AUTOSAR XML (schema 4-2-1)
package /VehicleProject
  system System
package /TP
  can tp config FD1_CAN: communication-cluster=FD1_CAN, can-tp-ecu{cycle-time-main-function=0.005, ecu-instance=PSCM_FD}
    can tp channel TPCH: channel-id=0, channel-mode=FULL-DUPLEX-MODE
    can-tp-connection addressing-format=STANDARD, can-tp-channel=TPCH, data-pdu=TesterFunctionalReq_FD1_Tp_oFD1_CAN, receiver=TN_PSCM_FD_FD, ta-type=FUNCTIONAL-CAN-FD, tp-sdu=TesterFunctionalReq_FD1_oFD1_CAN, transmitter=TN_TSTR_FD:
      ident TesterFunctionalReq_FD1_FD_oTN_TSTR_FD
    can-tp-connection addressing-format=STANDARD, can-tp-channel=TPCH, data-pdu=TesterFunctionalReq_FD1_Tp_oFD1_CAN_20, receiver=TN_PSCM_FD, ta-type=FUNCTIONAL, tp-sdu=TesterFunctionalReq_FD1_oFD1_CAN_20, transmitter=TN_TSTR:
      ident TesterFunctionalReq_FD1_oTN_TSTR
    can-tp-connection addressing-format=STANDARD, can-tp-channel=TPCH, data-pdu=TesterPhysicalReqPSCM_FD1_Tp_oFD1_CAN_20, flow-control-pdu=TesterPhysicalResPSCM_FD1_Tp_oFD1_CAN_20, receiver=TN_PSCM_FD, ta-type=PHYSICAL, tp-sdu=TesterPhysicalReqPSCM_FD1_oFD1_CAN_20, transmitter=TN_TSTR:
      ident TesterPhysicalReqPSCM_FD1_oTN_PSCM_FD
    can-tp-connection addressing-format=STANDARD, can-tp-channel=TPCH, data-pdu=TesterPhysicalReqPSCM_FD1_Tp_oFD1_CAN, flow-control-pdu=TesterPhysicalResPSCM_FD1_Tp_oFD1_CAN, receiver=TN_PSCM_FD_FD, ta-type=PHYSICAL-CAN-FD, tp-sdu=TesterPhysicalReqPSCM_FD1_oFD1_CAN, transmitter=TN_TSTR_FD:
      ident TesterPhysicalReqPSCM_FD1_oTN_PSCM_FD_FD
    can-tp-connection addressing-format=STANDARD, can-tp-channel=TPCH, data-pdu=TesterPhysicalResPSCM_FD1_Tp_oFD1_CAN_20, flow-control-pdu=TesterPhysicalReqPSCM_FD1_Tp_oFD1_CAN_20, receiver=TN_TSTR, ta-type=PHYSICAL, tp-sdu=TesterPhysicalResPSCM_FD1_oFD1_CAN_20, transmitter=TN_PSCM_FD:
      ident TesterPhysicalResPSCM_FD1_oTN_PSCM_FD
    can-tp-connection addressing-format=STANDARD, can-tp-channel=TPCH, data-pdu=TesterPhysicalResPSCM_FD1_Tp_oFD1_CAN, flow-control-pdu=TesterPhysicalReqPSCM_FD1_Tp_oFD1_CAN, receiver=TN_TSTR_FD, ta-type=PHYSICAL-CAN-FD, tp-sdu=TesterPhysicalResPSCM_FD1_oFD1_CAN, transmitter=TN_PSCM_FD_FD:
      ident TesterPhysicalResPSCM_FD1_oTN_PSCM_FD_FD
    4 x can tp node:
      TN_PSCM_FD: connector=CN_FD1_CAN
      TN_PSCM_FD_FD: connector=CN_FD1_CAN
      TN_TSTR
      TN_TSTR_FD
package /Cluster
  can cluster FD1_CAN: baudrate=500000, protocol-name=CAN, can-fd-baudrate=500000  # FD1_CAN_P702_GASD_MY21_V05 | New CAN FD network
    can physical channel CHNL: comm-connectors=CN_FD1_CAN
      frame ABS_BrkBst_Data_FD1_oFD1_CAN: id 0x4B0, to PSCM_FD, frame-length=8, can-addressing-mode=STANDARD, can-frame-rx-behavior=ANY, can-frame-tx-behavior=CAN-FD
        pdu ABS_BrkBst_Data_FD1_oFD1_CAN: length=8, minimum-delay=0.01, transmission-mode-false-timing=cyclic-timing={time-offset=0, time-period=0.02}, transmission-mode-true-timing=cyclic-timing={time-offset=0, time-period=0.02}, unused-bit-pattern=0
          signal YawStabilityIndex_oABS_BrkBst_Data_FD1_oFD1_CAN: start 0, 9 bit, big-endian, init-value=256, base-type=uint16, compu-method=CM_YawStabilityIndex, unit=U_p, transfer-property=PENDING, to PSCM_FD
      frame ActiveFrontStrg_Stat2_FD1_oFD1_CAN: id 0x8A, to PSCM_FD, frame-length=8, can-addressing-mode=STANDARD, can-frame-rx-behavior=ANY, can-frame-tx-behavior=CAN-FD
        pdu ActiveFrontStrg_Stat2_FD1_oFD1_CAN: length=8, minimum-delay=0.02, unused-bit-pattern=0
          signal SteWhlRelCalib_An_Sns_oActiveFrontStrg_Stat2_FD1_oFD1_CAN: start 15, 15 bit, big-endian, init-value=0, base-type=uint16, compu-method=CM_SteWhlRelCalib_An_Sns, unit=U_deg, transfer-property=PENDING, to PSCM_FD  # Signal is not transmitted on vehicles where PSCM is transmitting the message that contains this signal. Signal data set to 0x0 for ABS only vehicle option content
      frame APIM_Send_Signals_2_FD1_oFD1_CAN: id 0x215, to PSCM_FD, frame-length=8, can-addressing-mode=STANDARD, can-frame-rx-behavior=ANY, can-frame-tx-behavior=CAN-FD
        pdu APIM_Send_Signals_2_FD1_oFD1_CAN: length=8, minimum-delay=0.02, unused-bit-pattern=0
          signal TrlrAidMde_D_Rq_oAPIM_Send_Signals_2_FD1_oFD1_CAN: start 5, 2 bit, big-endian, init-value=0, base-type=uint8, compu-method=CM_TrlrAidMde_D_Rq, unit=U_SED, transfer-property=PENDING, to PSCM_FD
      frame APIM_Send_Signals1_FD1_oFD1_CAN: id 0x3F1, to PSCM_FD, frame-length=8, can-addressing-mode=STANDARD, can-frame-rx-behavior=ANY, can-frame-tx-behavior=CAN-FD  # APIM Tx
        pdu APIM_Send_Signals1_FD1_oFD1_CAN: length=8, minimum-delay=0.02, unused-bit-pattern=0
          signal TrlrAidCancl_B_Rq_oAPIM_Send_Signals1_FD1_oFD1_CAN: start 48, 1 bit, big-endian, init-value=0, base-type=boolean, compu-method=CM_TrlrAidCancl_B_Rq, unit=U_SED, transfer-property=PENDING, to PSCM_FD
      frame Body_Info_4_FD1_oFD1_CAN: id 0x242, to PSCM_FD, frame-length=8, can-addressing-mode=STANDARD, can-frame-rx-behavior=ANY, can-frame-tx-behavior=CAN-FD
        pdu Body_Info_4_FD1_oFD1_CAN: length=8, minimum-delay=0.02, unused-bit-pattern=0
          signal BattULo_U_Actl_oBody_Info_4_FD1_oFD1_CAN: start 39, 8 bit, big-endian, init-value=255, base-type=uint8, compu-method=CM_BattULo_U_Actl, unit=U_volt, transfer-property=PENDING, to PSCM_FD
      frame BodyInfo_3_FD1_oFD1_CAN: id 0x3B3, to PSCM_FD, frame-length=8, can-addressing-mode=STANDARD, can-frame-rx-behavior=ANY, can-frame-tx-behavior=CAN-FD
        pdu BodyInfo_3_FD1_oFD1_CAN: length=8, minimum-delay=0.02, unused-bit-pattern=0
          signal Ignition_Status_oBodyInfo_3_FD1_oFD1_CAN: start 7, 4 bit, big-endian, init-value=0, base-type=uint8, compu-method=CM_Ignition_Status, unit=U_SED, transfer-property=PENDING, to PSCM_FD
          signal LifeCycMde_D_Actl_oBodyInfo_3_FD1_oFD1_CAN: start 53, 4 bit, big-endian, init-value=0, base-type=uint8, compu-method=CM_LifeCycMde_D_Actl, unit=U_SED, transfer-property=PENDING, to PSCM_FD
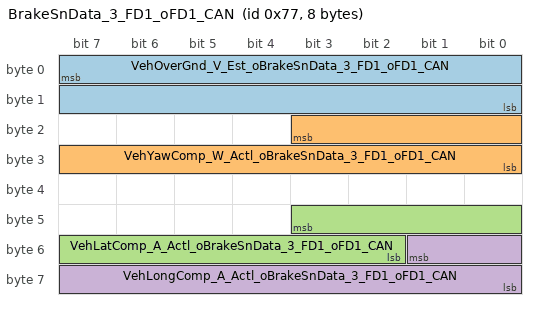
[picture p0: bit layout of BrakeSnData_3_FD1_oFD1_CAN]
      frame BrakeSnData_3_FD1_oFD1_CAN: id 0x77, to PSCM_FD, frame-length=8, can-addressing-mode=STANDARD, can-frame-rx-behavior=ANY, can-frame-tx-behavior=CAN-FD
        pdu BrakeSnData_3_FD1_oFD1_CAN: length=8, minimum-delay=0.01, transmission-mode-false-timing=cyclic-timing={time-offset=0, time-period=0.02}, transmission-mode-true-timing=cyclic-timing={time-offset=0, time-period=0.02}, unused-bit-pattern=0
          signal VehOverGnd_V_Est_oBrakeSnData_3_FD1_oFD1_CAN: start 7, 16 bit, big-endian, init-value=0, base-type=uint16, compu-method=CM_VehOverGnd_V_Est, unit=U_kph, transfer-property=PENDING, to PSCM_FD
          signal VehYawComp_W_Actl_oBrakeSnData_3_FD1_oFD1_CAN: start 19, 12 bit, big-endian, init-value=4094, base-type=uint16, compu-method=CM_VehYawComp_W_Actl, unit=U_degYs, transfer-property=PENDING, to PSCM_FD
          signal VehLatComp_A_Actl_oBrakeSnData_3_FD1_oFD1_CAN: start 43, 10 bit, big-endian, init-value=1022, base-type=uint16, compu-method=CM_VehLatComp_A_Actl, unit=U_mYsX2, transfer-property=PENDING, to PSCM_FD
          signal VehLongComp_A_Actl_oBrakeSnData_3_FD1_oFD1_CAN: start 49, 10 bit, big-endian, init-value=1022, base-type=uint16, compu-method=CM_VehLongComp_A_Actl, unit=U_mYsX2, transfer-property=PENDING, to PSCM_FD
      frame BrakeSnData_4_FD1_oFD1_CAN: id 0x7D, to PSCM_FD, frame-length=8, can-addressing-mode=STANDARD, can-frame-rx-behavior=ANY, can-frame-tx-behavior=CAN-FD
        pdu BrakeSnData_4_FD1_oFD1_CAN: length=8, minimum-delay=0.01, transmission-mode-false-timing=cyclic-timing={time-offset=0, time-period=0.02}, transmission-mode-true-timing=cyclic-timing={time-offset=0, time-period=0.02}, unused-bit-pattern=0
          signal BrkTot_Tq_Actl_oBrakeSnData_4_FD1_oFD1_CAN: start 27, 13 bit, big-endian, init-value=0, base-type=uint16, compu-method=CM_BrkTot_Tq_Actl, unit=U_Nm, transfer-property=PENDING, to PSCM_FD
          signal VehVertComp_A_Actl_oBrakeSnData_4_FD1_oFD1_CAN: start 45, 10 bit, big-endian, init-value=1022, base-type=uint16, compu-method=CM_VehVertComp_A_Actl, unit=U_mYsX2, transfer-property=PENDING, to PSCM_FD
      frame BrakeSnData_5_FD1_oFD1_CAN: id 0x76, to PSCM_FD, frame-length=8, can-addressing-mode=STANDARD, can-frame-rx-behavior=ANY, can-frame-tx-behavior=CAN-FD
        pdu BrakeSnData_5_FD1_oFD1_CAN: length=8, minimum-delay=0.02, transmission-mode-false-timing={cyclic-timing={time-offset=0, time-period=0.5}, event-controlled-timing={number-of-repetitions=0, repetition-period=0}}, transmission-mode-true-timing={cyclic-timing={time-offset=0, time-period=0.5}, event-controlled-timing={number-of-repetitions=0, repetition-period=0}}, unused-bit-pattern=0
          signal DrvSte_D_Stat_oBrakeSnData_5_FD1_oFD1_CAN: start 19, 4 bit, big-endian, init-value=0, base-type=uint8, compu-method=CM_DrvSte_D_Stat, unit=U_SED, transfer-property=TRIGGERED-ON-CHANGE-WITHOUT-REPETITION, to PSCM_FD
          signal DrvSte_Tq_Rq_oBrakeSnData_5_FD1_oFD1_CAN: start 31, 8 bit, big-endian, init-value=128, base-type=uint8, compu-method=CM_DrvSte_Tq_Rq, unit=U_Nm, transfer-property=PENDING, to PSCM_FD
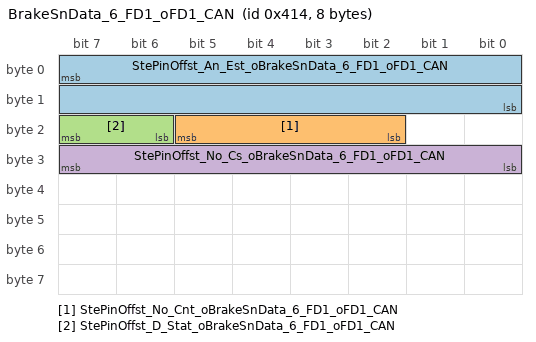
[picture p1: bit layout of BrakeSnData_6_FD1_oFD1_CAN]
      frame BrakeSnData_6_FD1_oFD1_CAN: id 0x414, to PSCM_FD, frame-length=8, can-addressing-mode=STANDARD, can-frame-rx-behavior=ANY, can-frame-tx-behavior=CAN-FD
        pdu BrakeSnData_6_FD1_oFD1_CAN: length=8, minimum-delay=0.02, transmission-mode-false-timing=cyclic-timing={time-offset=0, time-period=0.1}, transmission-mode-true-timing=cyclic-timing={time-offset=0, time-period=0.1}, unused-bit-pattern=0
          signal StePinOffst_An_Est_oBrakeSnData_6_FD1_oFD1_CAN: start 7, 16 bit, big-endian, init-value=65534, base-type=uint16, compu-method=CM_StePinOffst_An_Est, unit=U_degrees, transfer-property=PENDING, to PSCM_FD  # SASM will transmit these signals on vehicles with SASM and without PSCM. SCCM will not Tx this signal when SASM is present.
          signal StePinOffst_No_Cnt_oBrakeSnData_6_FD1_oFD1_CAN: start 21, 4 bit, big-endian, init-value=0, base-type=uint8, compu-method=CM_StePinOffst_No_Cnt, unit=unitless, transfer-property=PENDING, to PSCM_FD
          signal StePinOffst_D_Stat_oBrakeSnData_6_FD1_oFD1_CAN: start 23, 2 bit, big-endian, init-value=0, base-type=uint8, compu-method=CM_StePinOffst_D_Stat, unit=U_SED, transfer-property=PENDING, to PSCM_FD
          signal StePinOffst_No_Cs_oBrakeSnData_6_FD1_oFD1_CAN: start 31, 8 bit, big-endian, init-value=0, base-type=uint8, compu-method=CM_StePinOffst_No_Cs, unit=Unitless, transfer-property=PENDING, to PSCM_FD  # Signal not transmitted on gas variants.
      frame BrakeSysFeatures_3_oFD1_CAN: id 0x41E, to PSCM_FD, frame-length=8, can-addressing-mode=STANDARD, can-frame-rx-behavior=ANY, can-frame-tx-behavior=CAN-FD
        pdu BrakeSysFeatures_3_oFD1_CAN: length=8, minimum-delay=0.02, transmission-mode-false-timing={cyclic-timing={time-offset=0, time-period=1}, event-controlled-timing={number-of-repetitions=0, repetition-period=0}}, transmission-mode-true-timing={cyclic-timing={time-offset=0, time-period=1}, event-controlled-timing={number-of-repetitions=0, repetition-period=0}}, unused-bit-pattern=0
          signal SelDrvMdeChassis2_D_Rq_oBrakeSysFeatures_3_oFD1_CAN: start 45, 5 bit, big-endian, init-value=0, base-type=uint8, compu-method=CM_SelDrvMdeChassis2_D_Rq, unit=U_SED, transfer-property=TRIGGERED-ON-CHANGE-WITHOUT-REPETITION, to PSCM_FD
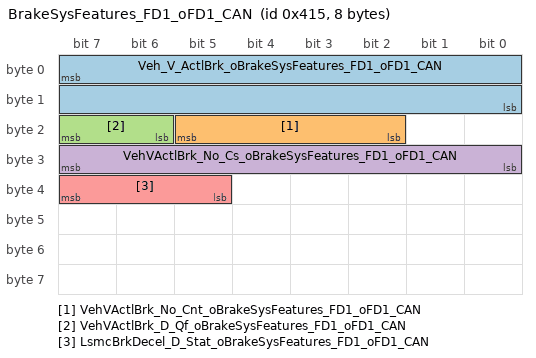
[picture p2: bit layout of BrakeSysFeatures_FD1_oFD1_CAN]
      frame BrakeSysFeatures_FD1_oFD1_CAN: id 0x415, to PSCM_FD, frame-length=8, can-addressing-mode=STANDARD, can-frame-rx-behavior=ANY, can-frame-tx-behavior=CAN-FD
        pdu BrakeSysFeatures_FD1_oFD1_CAN: length=8, minimum-delay=0.01, transmission-mode-false-timing=cyclic-timing={time-offset=0, time-period=0.02}, transmission-mode-true-timing=cyclic-timing={time-offset=0, time-period=0.02}, unused-bit-pattern=0
          signal Veh_V_ActlBrk_oBrakeSysFeatures_FD1_oFD1_CAN: start 7, 16 bit, big-endian, init-value=0, base-type=uint16, compu-method=CM_Veh_V_ActlBrk, unit=U_kph, transfer-property=PENDING, to PSCM_FD
          signal VehVActlBrk_No_Cnt_oBrakeSysFeatures_FD1_oFD1_CAN: start 21, 4 bit, big-endian, init-value=0, base-type=uint8, compu-method=CM_VehVActlBrk_No_Cnt, unit=Unitless, transfer-property=PENDING, to PSCM_FD
          signal VehVActlBrk_D_Qf_oBrakeSysFeatures_FD1_oFD1_CAN: start 23, 2 bit, big-endian, init-value=0, base-type=uint8, compu-method=CM_VehVActlBrk_D_Qf, unit=U_SED, transfer-property=PENDING, to PSCM_FD
          signal VehVActlBrk_No_Cs_oBrakeSysFeatures_FD1_oFD1_CAN: start 31, 8 bit, big-endian, init-value=0, base-type=uint8, compu-method=CM_VehVActlBrk_No_Cs, unit=Unitless, transfer-property=PENDING, to PSCM_FD
          signal LsmcBrkDecel_D_Stat_oBrakeSysFeatures_FD1_oFD1_CAN: start 39, 3 bit, big-endian, init-value=0, base-type=uint8, compu-method=CM_LsmcBrkDecel_D_Stat, unit=U_SED, transfer-property=PENDING, to PSCM_FD
      frame Climate_Control_Data_FD1_oFD1_CAN: id 0x41A, to PSCM_FD, frame-length=8, can-addressing-mode=STANDARD, can-frame-rx-behavior=ANY, can-frame-tx-behavior=CAN-FD
        pdu Climate_Control_Data_FD1_oFD1_CAN: length=8, minimum-delay=0.02, unused-bit-pattern=0
          signal Outside_Air_Temp_Stat_oClimate_Control_Data_FD1_oFD1_CAN: start 7, 8 bit, big-endian, init-value=254, base-type=uint8, compu-method=CM_Outside_Air_Temp_Stat, unit=U_Degrees_C, transfer-property=PENDING, to PSCM_FD  # Filtered value, i.e. same as disply for customer
      frame Cluster_Info1_FD1_oFD1_CAN: id 0x430, to PSCM_FD, frame-length=8, can-addressing-mode=STANDARD, can-frame-rx-behavior=ANY, can-frame-tx-behavior=CAN-FD
        pdu Cluster_Info1_FD1_oFD1_CAN: length=8, minimum-delay=0.02, unused-bit-pattern=0
          signal OdometerMasterValue_oCluster_Info1_FD1_oFD1_CAN: start 15, 24 bit, big-endian, init-value=0, base-type=uint32, compu-method=CM_OdometerMasterValue, unit=U_km, transfer-property=PENDING, to PSCM_FD
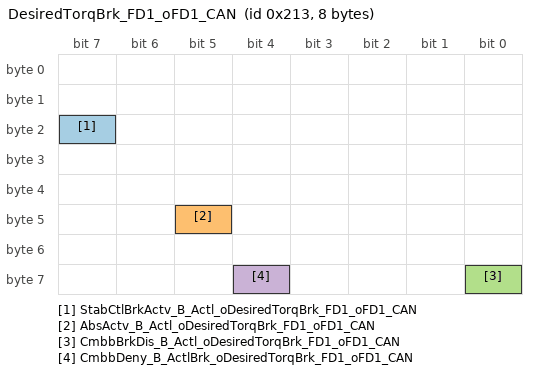
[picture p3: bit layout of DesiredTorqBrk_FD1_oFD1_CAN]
      frame DesiredTorqBrk_FD1_oFD1_CAN: id 0x213, to PSCM_FD, frame-length=8, can-addressing-mode=STANDARD, can-frame-rx-behavior=ANY, can-frame-tx-behavior=CAN-FD  # When PBM is present use 0x41B for PrkMsgTxt_D_Rq, PrkBrkRedLamp_D_Rq, PrkBrkYwLamp_D_Rq source signals otherwise ABS will source from 0x213.
        pdu DesiredTorqBrk_FD1_oFD1_CAN: length=8, minimum-delay=0.01, transmission-mode-false-timing=cyclic-timing={time-offset=0, time-period=0.02}, transmission-mode-true-timing=cyclic-timing={time-offset=0, time-period=0.02}, unused-bit-pattern=0
          signal StabCtlBrkActv_B_Actl_oDesiredTorqBrk_FD1_oFD1_CAN: start 23, 1 bit, big-endian, init-value=0, base-type=boolean, compu-method=CM_StabCtlBrkActv_B_Actl, unit=U_SED, transfer-property=PENDING, to PSCM_FD
          signal AbsActv_B_Actl_oDesiredTorqBrk_FD1_oFD1_CAN: start 45, 1 bit, big-endian, init-value=0, base-type=boolean, compu-method=CM_AbsActv_B_Actl, unit=U_SED, transfer-property=PENDING, to PSCM_FD
          signal CmbbBrkDis_B_Actl_oDesiredTorqBrk_FD1_oFD1_CAN: start 56, 1 bit, big-endian, init-value=0, base-type=boolean, compu-method=CM_CmbbBrkDis_B_Actl, unit=U_SED, transfer-property=PENDING, to PSCM_FD
          signal CmbbDeny_B_ActlBrk_oDesiredTorqBrk_FD1_oFD1_CAN: start 60, 1 bit, big-endian, init-value=0, base-type=boolean, compu-method=CM_CmbbDeny_B_ActlBrk, unit=U_SED, transfer-property=PENDING, to PSCM_FD
      frame EngBrakeData_FD1_oFD1_CAN: id 0x165, to PSCM_FD, frame-length=8, can-addressing-mode=STANDARD, can-frame-rx-behavior=ANY, can-frame-tx-behavior=CAN-FD
        pdu EngBrakeData_FD1_oFD1_CAN: length=8, minimum-delay=0.01, transmission-mode-false-timing=cyclic-timing={time-offset=0, time-period=0.02}, transmission-mode-true-timing=cyclic-timing={time-offset=0, time-period=0.02}, unused-bit-pattern=0
          signal BpedDrvAppl_D_Actl_oEngBrakeData_FD1_oFD1_CAN: start 5, 2 bit, big-endian, init-value=1, base-type=uint8, compu-method=CM_BpedDrvAppl_D_Actl, unit=U_SED, transfer-property=PENDING, to PSCM_FD  # CCMGenSigTimeoutTime=1000
          signal BPedDrvAppl_D_QF_oEngBrakeData_FD1_oFD1_CAN: start 15, 2 bit, big-endian, init-value=1, base-type=uint8, compu-method=CM_BPedDrvAppl_D_QF, unit=U_SED, transfer-property=PENDING, to PSCM_FD
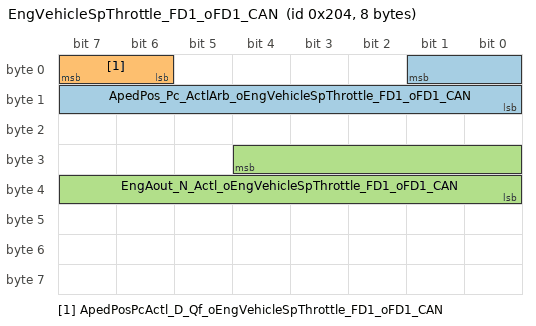
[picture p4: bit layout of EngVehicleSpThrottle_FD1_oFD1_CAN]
      frame EngVehicleSpThrottle_FD1_oFD1_CAN: id 0x204, to PSCM_FD, frame-length=8, can-addressing-mode=STANDARD, can-frame-rx-behavior=ANY, can-frame-tx-behavior=CAN-FD
        pdu EngVehicleSpThrottle_FD1_oFD1_CAN: length=8, minimum-delay=0, transmission-mode-false-timing=cyclic-timing={time-offset=0, time-period=0.01}, transmission-mode-true-timing=cyclic-timing={time-offset=0, time-period=0.01}, unused-bit-pattern=0
          signal ApedPos_Pc_ActlArb_oEngVehicleSpThrottle_FD1_oFD1_CAN: start 1, 10 bit, big-endian, init-value=0, base-type=uint16, compu-method=CM_ApedPos_Pc_ActlArb, unit=U_p, transfer-property=PENDING, to PSCM_FD  # ABSGenSigTimeoutTime=1000
          signal ApedPosPcActl_D_Qf_oEngVehicleSpThrottle_FD1_oFD1_CAN: start 7, 2 bit, big-endian, init-value=1, base-type=uint8, compu-method=CM_ApedPosPcActl_D_Qf, unit=U_SED, transfer-property=PENDING, to PSCM_FD
          signal EngAout_N_Actl_oEngVehicleSpThrottle_FD1_oFD1_CAN: start 28, 13 bit, big-endian, init-value=0, base-type=uint16, compu-method=CM_EngAout_N_Actl, unit=U_rpm, transfer-property=PENDING, to PSCM_FD
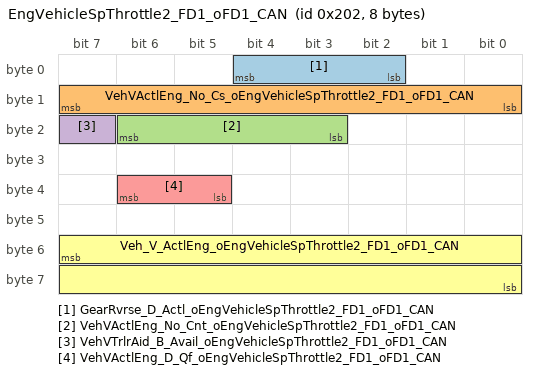
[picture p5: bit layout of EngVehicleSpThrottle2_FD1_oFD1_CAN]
      frame EngVehicleSpThrottle2_FD1_oFD1_CAN: id 0x202, to PSCM_FD, frame-length=8, can-addressing-mode=STANDARD, can-frame-rx-behavior=ANY, can-frame-tx-behavior=CAN-FD
        pdu EngVehicleSpThrottle2_FD1_oFD1_CAN: length=8, minimum-delay=0.01, transmission-mode-false-timing=cyclic-timing={time-offset=0, time-period=0.02}, transmission-mode-true-timing=cyclic-timing={time-offset=0, time-period=0.02}, unused-bit-pattern=0
          signal GearRvrse_D_Actl_oEngVehicleSpThrottle2_FD1_oFD1_CAN: start 4, 3 bit, big-endian, init-value=7, base-type=uint8, compu-method=CM_GearRvrse_D_Actl, unit=U_SED, transfer-property=PENDING, to PSCM_FD  # Do not implement GearRvrse_D_Actl until eTracker 8804151 is approved, 11/24/09
          signal VehVActlEng_No_Cs_oEngVehicleSpThrottle2_FD1_oFD1_CAN: start 15, 8 bit, big-endian, init-value=0, base-type=uint8, compu-method=CM_VehVActlEng_No_Cs, unit=Unitless, transfer-property=PENDING, to PSCM_FD
          signal VehVActlEng_No_Cnt_oEngVehicleSpThrottle2_FD1_oFD1_CAN: start 22, 4 bit, big-endian, init-value=0, base-type=uint8, compu-method=CM_VehVActlEng_No_Cnt, unit=Unitless, transfer-property=PENDING, to PSCM_FD
          signal VehVTrlrAid_B_Avail_oEngVehicleSpThrottle2_FD1_oFD1_CAN: start 23, 1 bit, big-endian, init-value=0, base-type=boolean, compu-method=CM_VehVTrlrAid_B_Avail, unit=U_SED, transfer-property=PENDING, to PSCM_FD
          signal VehVActlEng_D_Qf_oEngVehicleSpThrottle2_FD1_oFD1_CAN: start 38, 2 bit, big-endian, init-value=0, base-type=uint8, compu-method=CM_VehVActlEng_D_Qf, unit=U_SED, transfer-property=PENDING, to PSCM_FD
          signal Veh_V_ActlEng_oEngVehicleSpThrottle2_FD1_oFD1_CAN: start 55, 16 bit, big-endian, init-value=0, base-type=uint16, compu-method=CM_Veh_V_ActlEng, unit=U_kph, transfer-property=PENDING, to PSCM_FD
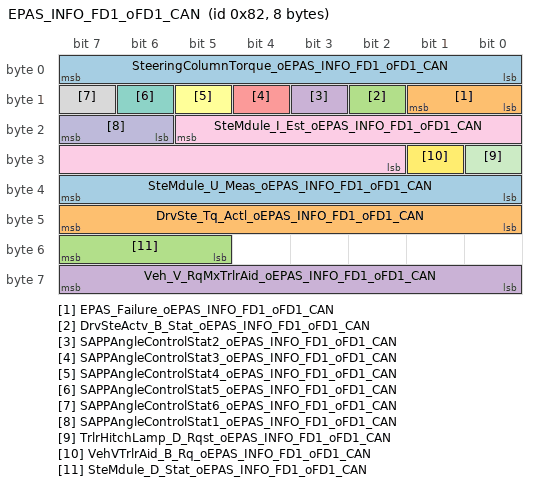
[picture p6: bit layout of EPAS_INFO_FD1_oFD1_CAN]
      frame EPAS_INFO_FD1_oFD1_CAN: id 0x82, from PSCM_FD, frame-length=8, variation-point=post-build-variant-condition{matching-criterion=Communication, value=0}, can-addressing-mode=STANDARD, can-frame-rx-behavior=ANY, can-frame-tx-behavior=CAN-FD  # drecker 10/23/09 Need SAPP in sync w/Strg Torque for proper PAM interpretation, else fault msg's displayed FP@20ms IPC needs EPAS_Failure for msg to driver. Not map w/Lane Assist FP@30s FP), save bandwidth if feature not on vehicle
        pdu EPAS_INFO_FD1_oFD1_CAN: length=8, minimum-delay=0.01, transmission-mode-false-timing=cyclic-timing={time-offset=0, time-period=0.02}, transmission-mode-true-timing=cyclic-timing={time-offset=0, time-period=0.02}, unused-bit-pattern=0
          signal SteeringColumnTorque_oEPAS_INFO_FD1_oFD1_CAN: start 7, 8 bit, big-endian, init-value=254, base-type=uint8, compu-method=CM_SteeringColumnTorque, unit=U_Nm, transfer-property=PENDING
          signal EPAS_Failure_oEPAS_INFO_FD1_oFD1_CAN: start 9, 2 bit, big-endian, init-value=0, base-type=uint8, compu-method=CM_EPAS_Failure, unit=U_SED, transfer-property=PENDING
          signal DrvSteActv_B_Stat_oEPAS_INFO_FD1_oFD1_CAN: start 10, 1 bit, big-endian, init-value=0, base-type=boolean, compu-method=CM_DrvSteActv_B_Stat, unit=U_SED, transfer-property=PENDING
          signal SAPPAngleControlStat2_oEPAS_INFO_FD1_oFD1_CAN: start 11, 1 bit, big-endian, init-value=0, base-type=boolean, compu-method=CM_SAPPAngleControlStat2, unit=U_SED, transfer-property=PENDING
          signal SAPPAngleControlStat3_oEPAS_INFO_FD1_oFD1_CAN: start 12, 1 bit, big-endian, init-value=0, base-type=boolean, compu-method=CM_SAPPAngleControlStat3, unit=U_SED, transfer-property=PENDING
          signal SAPPAngleControlStat4_oEPAS_INFO_FD1_oFD1_CAN: start 13, 1 bit, big-endian, init-value=0, base-type=boolean, compu-method=CM_SAPPAngleControlStat4, unit=U_SED, transfer-property=PENDING
          signal SAPPAngleControlStat5_oEPAS_INFO_FD1_oFD1_CAN: start 14, 1 bit, big-endian, init-value=0, base-type=boolean, compu-method=CM_SAPPAngleControlStat5, unit=U_SED, transfer-property=PENDING
          signal SAPPAngleControlStat6_oEPAS_INFO_FD1_oFD1_CAN: start 15, 1 bit, big-endian, init-value=0, base-type=boolean, compu-method=CM_SAPPAngleControlStat6, unit=U_SED, transfer-property=PENDING
          signal SteMdule_I_Est_oEPAS_INFO_FD1_oFD1_CAN: start 21, 12 bit, big-endian, init-value=4095, base-type=uint16, compu-method=CM_SteMdule_I_Est, unit=U_Amps, transfer-property=PENDING  # DCR 1745 to update Tx from GWM to EP100ms. SteMdule_I_Est & SteMdule_U_Meas are used by BMS system & filtered. The filter uses standard periodic rate & changing to EP would adversely affect the filter.(jweinfur)
          signal SAPPAngleControlStat1_oEPAS_INFO_FD1_oFD1_CAN: start 23, 2 bit, big-endian, init-value=0, base-type=uint8, compu-method=CM_SAPPAngleControlStat1, unit=U_SED, transfer-property=PENDING
          signal TrlrHitchLamp_D_Rqst_oEPAS_INFO_FD1_oFD1_CAN: start 24, 1 bit, big-endian, init-value=0, base-type=boolean, compu-method=CM_TrlrHitchLamp_D_Rqst, unit=U_SED, transfer-property=PENDING
          signal VehVTrlrAid_B_Rq_oEPAS_INFO_FD1_oFD1_CAN: start 25, 1 bit, big-endian, init-value=0, base-type=boolean, compu-method=CM_VehVTrlrAid_B_Rq, unit=U_SED, transfer-property=PENDING  # VR session start- req. limit blower speed no more than X volts. CC restriction on time msg. will be honored.Double Event msg1st event to request limit, 2nd event to release limit, No msg. CC Grammar v7.xls
          signal SteMdule_U_Meas_oEPAS_INFO_FD1_oFD1_CAN: start 39, 8 bit, big-endian, init-value=255, base-type=uint8, compu-method=CM_SteMdule_U_Meas, unit=U_Volts, transfer-property=PENDING  # DCR 1745 to update Tx from GWM to EP100ms. SteMdule_I_Est & SteMdule_U_Meas are used by BMS system & filtered. The filter uses standard periodic rate & changing to EP would adversely affect the filter.(jweinfur)
          signal DrvSte_Tq_Actl_oEPAS_INFO_FD1_oFD1_CAN: start 47, 8 bit, big-endian, init-value=128, base-type=uint8, compu-method=CM_DrvSte_Tq_Actl, unit=U_Nm, transfer-property=PENDING
          signal SteMdule_D_Stat_oEPAS_INFO_FD1_oFD1_CAN: start 55, 3 bit, big-endian, init-value=0, base-type=uint8, compu-method=CM_SteMdule_D_Stat, unit=U_SED, transfer-property=PENDING
          signal Veh_V_RqMxTrlrAid_oEPAS_INFO_FD1_oFD1_CAN: start 63, 8 bit, big-endian, init-value=255, base-type=uint8, compu-method=CM_Veh_V_RqMxTrlrAid, unit=U_kmYh, transfer-property=PENDING
      frame GGCC_Config_Mgmt_ID_1_FD1_oFD1_CAN: id 0x40A, to PSCM_FD, frame-length=8, can-addressing-mode=STANDARD, can-frame-rx-behavior=ANY, can-frame-tx-behavior=CAN-FD
        pdu GGCC_Config_Mgmt_ID_1_FD1_oFD1_CAN: length=8, minimum-delay=0.02, unused-bit-pattern=0
          signal VehicleGGCCData_oGGCC_Config_Mgmt_ID_1_FD1_oFD1_CAN: start 0, 64 bit, opaque, init-value=8 x 0, base-type=uint8_8_iso_8859_1, compu-method=CM_VehicleGGCCData, unit=U_mixed, transfer-property=PENDING, to PSCM_FD  # RCMGenSigTimeout=6000
      frame Image_Processing_Data_FD1_oFD1_CAN: id 0x451, to PSCM_FD, frame-length=8, can-addressing-mode=STANDARD, can-frame-rx-behavior=ANY, can-frame-tx-behavior=CAN-FD
        pdu Image_Processing_Data_FD1_oFD1_CAN: length=8, minimum-delay=0.02, transmission-mode-false-timing={cyclic-timing={time-offset=0, time-period=1}, event-controlled-timing={number-of-repetitions=0, repetition-period=0}}, transmission-mode-true-timing={cyclic-timing={time-offset=0, time-period=1}, event-controlled-timing={number-of-repetitions=0, repetition-period=0}}, unused-bit-pattern=0
          signal TrlrRvrseEnbl_D2_Stat_oImage_Processing_Data_FD1_oFD1_CAN: start 18, 3 bit, big-endian, init-value=0, base-type=uint8, compu-method=CM_TrlrRvrseEnbl_D2_Stat, unit=U_SED, transfer-property=TRIGGERED-ON-CHANGE-WITHOUT-REPETITION, to PSCM_FD
          signal TrlrRvrseMsgTxt_D2_Rq_oImage_Processing_Data_FD1_oFD1_CAN: start 31, 6 bit, big-endian, init-value=0, base-type=uint8, compu-method=CM_TrlrRvrseMsgTxt_D2_Rq, unit=U_SED, transfer-property=TRIGGERED-ON-CHANGE-WITHOUT-REPETITION, to PSCM_FD
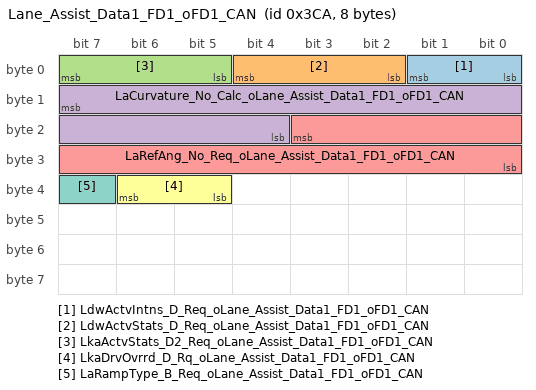
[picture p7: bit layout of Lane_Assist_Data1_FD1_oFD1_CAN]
      frame Lane_Assist_Data1_FD1_oFD1_CAN: id 0x3CA, to PSCM_FD, frame-length=8, can-addressing-mode=STANDARD, can-frame-rx-behavior=ANY, can-frame-tx-behavior=CAN-FD
        pdu Lane_Assist_Data1_FD1_oFD1_CAN: length=8, minimum-delay=0.01, unused-bit-pattern=0
          signal LdwActvIntns_D_Req_oLane_Assist_Data1_FD1_oFD1_CAN: start 1, 2 bit, big-endian, init-value=0, base-type=uint8, compu-method=CM_LdwActvIntns_D_Req, unit=U_SED, transfer-property=PENDING, to PSCM_FD
          signal LdwActvStats_D_Req_oLane_Assist_Data1_FD1_oFD1_CAN: start 4, 3 bit, big-endian, init-value=0, base-type=uint8, compu-method=CM_LdwActvStats_D_Req, unit=U_SED, transfer-property=PENDING, to PSCM_FD
          signal LkaActvStats_D2_Req_oLane_Assist_Data1_FD1_oFD1_CAN: start 7, 3 bit, big-endian, init-value=0, base-type=uint8, compu-method=CM_LkaActvStats_D2_Req, unit=U_SED, transfer-property=PENDING, to PSCM_FD
          signal LaCurvature_No_Calc_oLane_Assist_Data1_FD1_oFD1_CAN: start 15, 12 bit, big-endian, init-value=2048, base-type=uint16, compu-method=CM_LaCurvature_No_Calc, unit=U_1Ym, transfer-property=PENDING, to PSCM_FD
          signal LaRefAng_No_Req_oLane_Assist_Data1_FD1_oFD1_CAN: start 19, 12 bit, big-endian, init-value=2048, base-type=uint16, compu-method=CM_LaRefAng_No_Req, unit=U_mrad, transfer-property=PENDING, to PSCM_FD
          signal LkaDrvOvrrd_D_Rq_oLane_Assist_Data1_FD1_oFD1_CAN: start 38, 2 bit, big-endian, init-value=0, base-type=uint8, compu-method=CM_LkaDrvOvrrd_D_Rq, unit=U_SED, transfer-property=PENDING, to PSCM_FD
          signal LaRampType_B_Req_oLane_Assist_Data1_FD1_oFD1_CAN: start 39, 1 bit, big-endian, init-value=0, base-type=boolean, compu-method=CM_LaRampType_B_Req, unit=U_SED, transfer-property=PENDING, to PSCM_FD
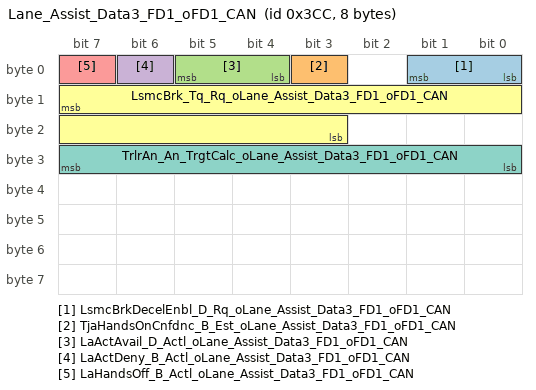
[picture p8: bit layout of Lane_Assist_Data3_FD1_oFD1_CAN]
      frame Lane_Assist_Data3_FD1_oFD1_CAN: id 0x3CC, from PSCM_FD, frame-length=8, variation-point=post-build-variant-condition{matching-criterion=Communication, value=0}, can-addressing-mode=STANDARD, can-frame-rx-behavior=ANY, can-frame-tx-behavior=CAN-FD
        pdu Lane_Assist_Data3_FD1_oFD1_CAN: length=8, minimum-delay=0.01, transmission-mode-false-timing=cyclic-timing={time-offset=0, time-period=0.03}, transmission-mode-true-timing=cyclic-timing={time-offset=0, time-period=0.03}, unused-bit-pattern=0
          signal LsmcBrkDecelEnbl_D_Rq_oLane_Assist_Data3_FD1_oFD1_CAN: start 1, 2 bit, big-endian, init-value=0, base-type=uint8, compu-method=CM_LsmcBrkDecelEnbl_D_Rq, unit=U_SED, transfer-property=PENDING
          signal TjaHandsOnCnfdnc_B_Est_oLane_Assist_Data3_FD1_oFD1_CAN: start 3, 1 bit, big-endian, init-value=1, base-type=boolean, compu-method=CM_TjaHandsOnCnfdnc_B_Est, unit=U_SED, transfer-property=PENDING
          signal LaActAvail_D_Actl_oLane_Assist_Data3_FD1_oFD1_CAN: start 5, 2 bit, big-endian, init-value=0, base-type=uint8, compu-method=CM_LaActAvail_D_Actl, unit=U_SED, transfer-property=PENDING
          signal LaActDeny_B_Actl_oLane_Assist_Data3_FD1_oFD1_CAN: start 6, 1 bit, big-endian, init-value=0, base-type=boolean, compu-method=CM_LaActDeny_B_Actl, unit=U_SED, transfer-property=PENDING
          signal LaHandsOff_B_Actl_oLane_Assist_Data3_FD1_oFD1_CAN: start 7, 1 bit, big-endian, init-value=1, base-type=boolean, compu-method=CM_LaHandsOff_B_Actl, unit=U_SED, transfer-property=PENDING
          signal LsmcBrk_Tq_Rq_oLane_Assist_Data3_FD1_oFD1_CAN: start 15, 13 bit, big-endian, init-value=0, base-type=uint16, compu-method=CM_LsmcBrk_Tq_Rq, unit=U_Nm, transfer-property=PENDING
          signal TrlrAn_An_TrgtCalc_oLane_Assist_Data3_FD1_oFD1_CAN: start 31, 8 bit, big-endian, init-value=128, base-type=uint8, compu-method=CM_TrlrAn_An_TrgtCalc, unit=U_degrees, transfer-property=PENDING
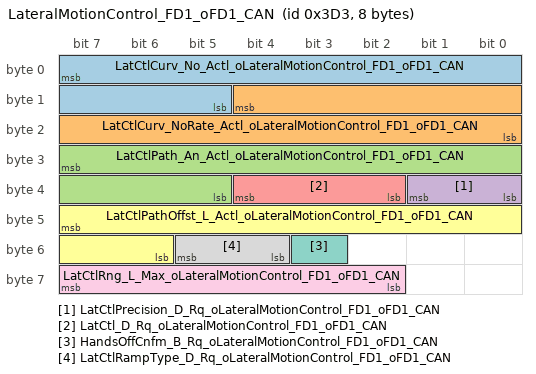
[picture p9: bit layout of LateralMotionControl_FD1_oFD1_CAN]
      frame LateralMotionControl_FD1_oFD1_CAN: id 0x3D3, to PSCM_FD, frame-length=8, can-addressing-mode=STANDARD, can-frame-rx-behavior=ANY, can-frame-tx-behavior=CAN-FD
        pdu LateralMotionControl_FD1_oFD1_CAN: length=8, minimum-delay=0.02, unused-bit-pattern=0
          signal LatCtlCurv_No_Actl_oLateralMotionControl_FD1_oFD1_CAN: start 7, 11 bit, big-endian, init-value=1000, base-type=uint16, compu-method=CM_LatCtlCurv_No_Actl, unit=U_1Ymeter, transfer-property=PENDING, to PSCM_FD
          signal LatCtlCurv_NoRate_Actl_oLateralMotionControl_FD1_oFD1_CAN: start 12, 13 bit, big-endian, init-value=4096, base-type=uint16, compu-method=CM_LatCtlCurv_NoRate_Actl, unit=U_1Ymeter, transfer-property=PENDING, to PSCM_FD
          signal LatCtlPath_An_Actl_oLateralMotionControl_FD1_oFD1_CAN: start 31, 11 bit, big-endian, init-value=1000, base-type=uint16, compu-method=CM_LatCtlPath_An_Actl, unit=U_radians, transfer-property=PENDING, to PSCM_FD
          signal LatCtlPrecision_D_Rq_oLateralMotionControl_FD1_oFD1_CAN: start 33, 2 bit, big-endian, init-value=0, base-type=uint8, compu-method=CM_LatCtlPrecision_D_Rq, unit=U_SED, transfer-property=PENDING, to PSCM_FD
          signal LatCtl_D_Rq_oLateralMotionControl_FD1_oFD1_CAN: start 36, 3 bit, big-endian, init-value=0, base-type=uint8, compu-method=CM_LatCtl_D_Rq, unit=U_SED, transfer-property=PENDING, to PSCM_FD
          signal LatCtlPathOffst_L_Actl_oLateralMotionControl_FD1_oFD1_CAN: start 47, 10 bit, big-endian, init-value=512, base-type=uint16, compu-method=CM_LatCtlPathOffst_L_Actl, unit=U_meter, transfer-property=PENDING, to PSCM_FD
          signal HandsOffCnfm_B_Rq_oLateralMotionControl_FD1_oFD1_CAN: start 51, 1 bit, big-endian, init-value=0, base-type=boolean, compu-method=CM_HandsOffCnfm_B_Rq, unit=U_SED, transfer-property=PENDING, to PSCM_FD
          signal LatCtlRampType_D_Rq_oLateralMotionControl_FD1_oFD1_CAN: start 53, 2 bit, big-endian, init-value=0, base-type=uint8, compu-method=CM_LatCtlRampType_D_Rq, unit=U_SED, transfer-property=PENDING, to PSCM_FD
          signal LatCtlRng_L_Max_oLateralMotionControl_FD1_oFD1_CAN: start 63, 6 bit, big-endian, init-value=0, base-type=uint8, compu-method=CM_LatCtlRng_L_Max, unit=U_meter, transfer-property=PENDING, to PSCM_FD
      frame Mc_Send_Signals_2_FD1_oFD1_CAN: id 0x2FD, to PSCM_FD, frame-length=8, can-addressing-mode=STANDARD, can-frame-rx-behavior=ANY, can-frame-tx-behavior=CAN-FD
        pdu Mc_Send_Signals_2_FD1_oFD1_CAN: length=8, minimum-delay=0.02, unused-bit-pattern=0
          signal EsaOn_B_Rq_oMc_Send_Signals_2_FD1_oFD1_CAN: start 15, 1 bit, big-endian, init-value=1, base-type=boolean, compu-method=CM_EsaOn_B_Rq, unit=U_SED, transfer-property=PENDING, to PSCM_FD
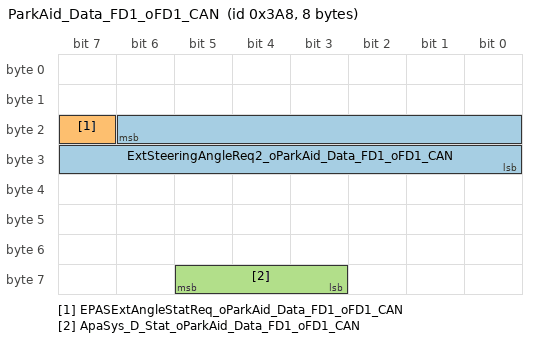
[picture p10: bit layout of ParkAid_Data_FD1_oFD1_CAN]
      frame ParkAid_Data_FD1_oFD1_CAN: id 0x3A8, to PSCM_FD, frame-length=8, can-addressing-mode=STANDARD, can-frame-rx-behavior=ANY, can-frame-tx-behavior=CAN-FD
        pdu ParkAid_Data_FD1_oFD1_CAN: length=8, minimum-delay=0.01, transmission-mode-false-timing=cyclic-timing={time-offset=0, time-period=0.02}, transmission-mode-true-timing=cyclic-timing={time-offset=0, time-period=0.02}, unused-bit-pattern=0
          signal ExtSteeringAngleReq2_oParkAid_Data_FD1_oFD1_CAN: start 22, 15 bit, big-endian, init-value=0, base-type=uint16, compu-method=CM_ExtSteeringAngleReq2, unit=U_Degrees, transfer-property=PENDING, to PSCM_FD
          signal EPASExtAngleStatReq_oParkAid_Data_FD1_oFD1_CAN: start 23, 1 bit, big-endian, init-value=0, base-type=boolean, compu-method=CM_EPASExtAngleStatReq, unit=U_SED, transfer-property=PENDING, to PSCM_FD
          signal ApaSys_D_Stat_oParkAid_Data_FD1_oFD1_CAN: start 61, 3 bit, big-endian, init-value=0, base-type=uint8, compu-method=CM_ApaSys_D_Stat, unit=U_SED, transfer-property=PENDING, to PSCM_FD
      frame PowertrainData_10_FD1_oFD1_CAN: id 0x176, to PSCM_FD, frame-length=8, can-addressing-mode=STANDARD, can-frame-rx-behavior=ANY, can-frame-tx-behavior=CAN-FD  # Programs w/o HS1 0x172 will need HS1 0x176 for GearPos_D_Actl. Future MY Programs that choose c/o still require HS1 0x172.
        pdu PowertrainData_10_FD1_oFD1_CAN: length=8, minimum-delay=0.02, transmission-mode-false-timing={cyclic-timing={time-offset=0, time-period=0.1}, event-controlled-timing={number-of-repetitions=0, repetition-period=0}}, transmission-mode-true-timing={cyclic-timing={time-offset=0, time-period=0.1}, event-controlled-timing={number-of-repetitions=0, repetition-period=0}}, unused-bit-pattern=0
          signal GearPos_D_Actl_oPowertrainData_10_FD1_oFD1_CAN: start 3, 4 bit, big-endian, init-value=15, base-type=uint8, compu-method=CM_GearPos_D_Actl, unit=U_SED, transfer-property=TRIGGERED-ON-CHANGE-WITHOUT-REPETITION, to PSCM_FD  # Powersplit HEVs with HF45, HPCM will Tx this message. For all other programs it will be Tx by PCM or TCM.
          signal TrnRng_D_Rq_oPowertrainData_10_FD1_oFD1_CAN: start 27, 4 bit, big-endian, init-value=14, base-type=uint8, compu-method=CM_TrnRng_D_Rq, unit=U_SED, transfer-property=TRIGGERED-ON-CHANGE-WITHOUT-REPETITION, to PSCM_FD  # Powersplit HEVs with HF45, HPCM will Tx this message. For all other programs it will be Tx by PCM or TCM.
      frame PSCM_AutoSar_NetwrkMgt_FD1_oFD1_CAN: id 0x5B5, from PSCM_FD, frame-length=8, variation-point=post-build-variant-condition{matching-criterion=Communication, value=0}, can-addressing-mode=STANDARD, can-frame-rx-behavior=ANY, can-frame-tx-behavior=CAN-FD
        nm pdu PSCM_AutoSar_NetwrkMgt_FD1_oFD1_CAN: length=8, unused-bit-pattern=0
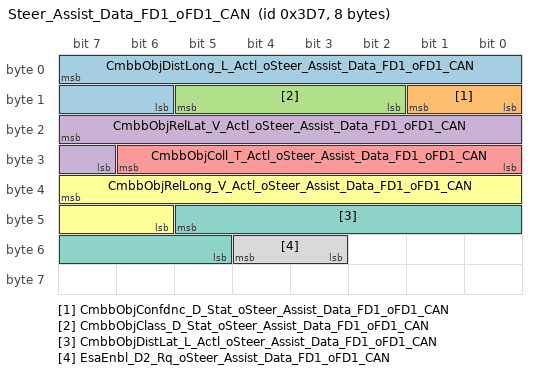
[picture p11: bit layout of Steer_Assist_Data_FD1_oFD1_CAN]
      frame Steer_Assist_Data_FD1_oFD1_CAN: id 0x3D7, to PSCM_FD, frame-length=8, can-addressing-mode=STANDARD, can-frame-rx-behavior=ANY, can-frame-tx-behavior=CAN-FD
        pdu Steer_Assist_Data_FD1_oFD1_CAN: length=8, minimum-delay=0.02, unused-bit-pattern=0
          signal CmbbObjDistLong_L_Actl_oSteer_Assist_Data_FD1_oFD1_CAN: start 7, 10 bit, big-endian, init-value=1022, base-type=uint16, compu-method=CM_CmbbObjDistLong_L_Actl, unit=U_meter, transfer-property=PENDING, to PSCM_FD
          signal CmbbObjConfdnc_D_Stat_oSteer_Assist_Data_FD1_oFD1_CAN: start 9, 2 bit, big-endian, init-value=0, base-type=uint8, compu-method=CM_CmbbObjConfdnc_D_Stat, unit=U_SED, transfer-property=PENDING, to PSCM_FD
          signal CmbbObjClass_D_Stat_oSteer_Assist_Data_FD1_oFD1_CAN: start 13, 4 bit, big-endian, init-value=0, base-type=uint8, compu-method=CM_CmbbObjClass_D_Stat, unit=U_SED, transfer-property=PENDING, to PSCM_FD
          signal CmbbObjRelLat_V_Actl_oSteer_Assist_Data_FD1_oFD1_CAN: start 23, 9 bit, big-endian, init-value=510, base-type=uint16, compu-method=CM_CmbbObjRelLat_V_Actl, unit=U_metersYsec, transfer-property=PENDING, to PSCM_FD
          signal CmbbObjColl_T_Actl_oSteer_Assist_Data_FD1_oFD1_CAN: start 30, 7 bit, big-endian, init-value=126, base-type=uint8, compu-method=CM_CmbbObjColl_T_Actl, unit=U_second, transfer-property=PENDING, to PSCM_FD
          signal CmbbObjRelLong_V_Actl_oSteer_Assist_Data_FD1_oFD1_CAN: start 39, 10 bit, big-endian, init-value=1022, base-type=uint16, compu-method=CM_CmbbObjRelLong_V_Actl, unit=U_metersYsec, transfer-property=PENDING, to PSCM_FD
          signal CmbbObjDistLat_L_Actl_oSteer_Assist_Data_FD1_oFD1_CAN: start 45, 9 bit, big-endian, init-value=510, base-type=uint16, compu-method=CM_CmbbObjDistLat_L_Actl, unit=U_meter, transfer-property=PENDING, to PSCM_FD
          signal EsaEnbl_D2_Rq_oSteer_Assist_Data_FD1_oFD1_CAN: start 52, 2 bit, big-endian, init-value=0, base-type=uint8, compu-method=CM_EsaEnbl_D2_Rq, unit=U_SED, transfer-property=PENDING, to PSCM_FD
      frame Steering_Data_FD1_oFD1_CAN: id 0x83, to PSCM_FD, frame-length=8, can-addressing-mode=STANDARD, can-frame-rx-behavior=ANY, can-frame-tx-behavior=CAN-FD
        pdu Steering_Data_FD1_oFD1_CAN: length=8, minimum-delay=0.02, unused-bit-pattern=0
          signal TurnLghtSwtch_D_Stat_oSteering_Data_FD1_oFD1_CAN: start 5, 2 bit, big-endian, init-value=0, base-type=uint8, compu-method=CM_TurnLghtSwtch_D_Stat, unit=U_SED, transfer-property=PENDING, to PSCM_FD
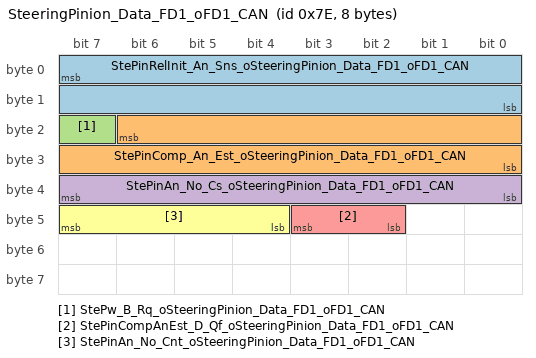
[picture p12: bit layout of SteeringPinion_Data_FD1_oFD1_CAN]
      frame SteeringPinion_Data_FD1_oFD1_CAN: id 0x7E, from PSCM_FD, frame-length=8, variation-point=post-build-variant-condition{matching-criterion=Communication, value=0}, can-addressing-mode=STANDARD, can-frame-rx-behavior=ANY, can-frame-tx-behavior=CAN-FD
        pdu SteeringPinion_Data_FD1_oFD1_CAN: length=8, minimum-delay=0, transmission-mode-false-timing=cyclic-timing={time-offset=0, time-period=0.01}, transmission-mode-true-timing=cyclic-timing={time-offset=0, time-period=0.01}, unused-bit-pattern=0
          signal StePinRelInit_An_Sns_oSteeringPinion_Data_FD1_oFD1_CAN: start 7, 16 bit, big-endian, init-value=65535, base-type=uint16, compu-method=CM_StePinRelInit_An_Sns, unit=U_degrees, transfer-property=PENDING  # SASM will transmit these signals on vehicles with SASM and without PSCM. SCCM will not Tx this signal when SASM is present.
          signal StePinComp_An_Est_oSteeringPinion_Data_FD1_oFD1_CAN: start 22, 15 bit, big-endian, init-value=16000, base-type=uint16, compu-method=CM_StePinComp_An_Est, unit=U_degrees, transfer-property=PENDING
          signal StePw_B_Rq_oSteeringPinion_Data_FD1_oFD1_CAN: start 23, 1 bit, big-endian, init-value=0, base-type=boolean, compu-method=CM_StePw_B_Rq, unit=U_SED, transfer-property=PENDING
          signal StePinAn_No_Cs_oSteeringPinion_Data_FD1_oFD1_CAN: start 39, 8 bit, big-endian, init-value=0, base-type=uint8, compu-method=CM_StePinAn_No_Cs, unit=Unitless, transfer-property=PENDING  # Signal not transmitted on gas variants.
          signal StePinCompAnEst_D_Qf_oSteeringPinion_Data_FD1_oFD1_CAN: start 43, 2 bit, big-endian, init-value=1, base-type=uint8, compu-method=CM_StePinCompAnEst_D_Qf, unit=U_SED, transfer-property=PENDING
          signal StePinAn_No_Cnt_oSteeringPinion_Data_FD1_oFD1_CAN: start 47, 4 bit, big-endian, init-value=0, base-type=uint8, compu-method=CM_StePinAn_No_Cnt, unit=unitless, transfer-property=PENDING
      frame TesterFunctionalReq_FD1_oFD1_CAN: id 0x7DF, to PSCM_FD, frame-length=64, variation-point=post-build-variant-condition{matching-criterion=Communication, value=0}, can-addressing-mode=STANDARD, can-frame-rx-behavior=CAN-FD, can-frame-tx-behavior=CAN-FD  # OBDII Request ($7DF) messages are for FNOS 1.0.1 only. Diagnostic Functional Addressing ($7DF) and Dual Rate Periodic messages are for FNOS I3 only.
        n pdu TesterFunctionalReq_FD1_Tp_oFD1_CAN: length=64
      frame TesterFunctionalReq_FD1_oFD1_CAN_20: id 0x7DF, to PSCM_FD, frame-length=8, variation-point=post-build-variant-condition{matching-criterion=Communication, value=0}, can-addressing-mode=STANDARD, can-frame-rx-behavior=CAN-20, can-frame-tx-behavior=CAN-20
        n pdu TesterFunctionalReq_FD1_Tp_oFD1_CAN_20: length=8
      frame TesterPhysicalReqPSCM_FD1_oFD1_CAN: id 0x730, to PSCM_FD, frame-length=64, variation-point=post-build-variant-condition{matching-criterion=Communication, value=0}, can-addressing-mode=STANDARD, can-frame-rx-behavior=CAN-FD, can-frame-tx-behavior=CAN-FD
        n pdu TesterPhysicalReqPSCM_FD1_Tp_oFD1_CAN: length=64
      frame TesterPhysicalReqPSCM_FD1_oFD1_CAN_20: id 0x730, to PSCM_FD, frame-length=8, variation-point=post-build-variant-condition{matching-criterion=Communication, value=0}, can-addressing-mode=STANDARD, can-frame-rx-behavior=CAN-20, can-frame-tx-behavior=CAN-20
        n pdu TesterPhysicalReqPSCM_FD1_Tp_oFD1_CAN_20: length=8
      frame TesterPhysicalResPSCM_FD1_oFD1_CAN: id 0x738, from PSCM_FD, frame-length=64, variation-point=post-build-variant-condition{matching-criterion=Communication, value=0}, can-addressing-mode=STANDARD, can-frame-rx-behavior=CAN-FD, can-frame-tx-behavior=CAN-FD
        n pdu TesterPhysicalResPSCM_FD1_Tp_oFD1_CAN: length=64
      frame TesterPhysicalResPSCM_FD1_oFD1_CAN_20: id 0x738, from PSCM_FD, frame-length=8, variation-point=post-build-variant-condition{matching-criterion=Communication, value=0}, can-addressing-mode=STANDARD, can-frame-rx-behavior=CAN-20, can-frame-tx-behavior=CAN-20
        n pdu TesterPhysicalResPSCM_FD1_Tp_oFD1_CAN_20: length=8
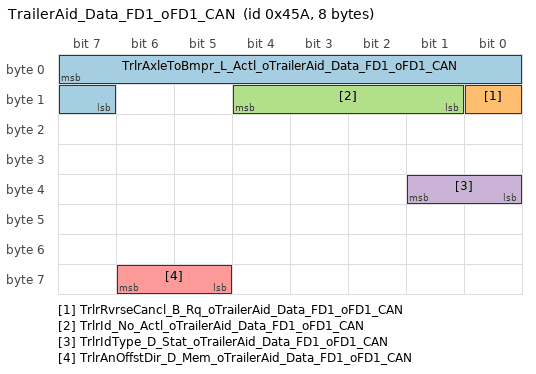
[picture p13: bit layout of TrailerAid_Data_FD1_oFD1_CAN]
      frame TrailerAid_Data_FD1_oFD1_CAN: id 0x45A, to PSCM_FD, frame-length=8, can-addressing-mode=STANDARD, can-frame-rx-behavior=ANY, can-frame-tx-behavior=CAN-FD
        pdu TrailerAid_Data_FD1_oFD1_CAN: length=8, minimum-delay=0.02, unused-bit-pattern=0
          signal TrlrAxleToBmpr_L_Actl_oTrailerAid_Data_FD1_oFD1_CAN: start 7, 9 bit, big-endian, init-value=0, base-type=uint16, compu-method=CM_TrlrAxleToBmpr_L_Actl, unit=U_meter, transfer-property=PENDING, to PSCM_FD
          signal TrlrRvrseCancl_B_Rq_oTrailerAid_Data_FD1_oFD1_CAN: start 8, 1 bit, big-endian, init-value=0, base-type=boolean, compu-method=CM_TrlrRvrseCancl_B_Rq, unit=U_SED, transfer-property=PENDING, to PSCM_FD
          signal TrlrId_No_Actl_oTrailerAid_Data_FD1_oFD1_CAN: start 12, 4 bit, big-endian, init-value=0, base-type=uint8, compu-method=CM_TrlrId_No_Actl, unit=unitless, transfer-property=PENDING, to PSCM_FD
          signal TrlrIdType_D_Stat_oTrailerAid_Data_FD1_oFD1_CAN: start 33, 2 bit, big-endian, init-value=0, base-type=uint8, compu-method=CM_TrlrIdType_D_Stat, unit=U_SED, transfer-property=PENDING, to PSCM_FD
          signal TrlrAnOffstDir_D_Mem_oTrailerAid_Data_FD1_oFD1_CAN: start 62, 2 bit, big-endian, init-value=0, base-type=uint8, compu-method=CM_TrlrAnOffstDir_D_Mem, unit=U_SED, transfer-property=PENDING, to PSCM_FD
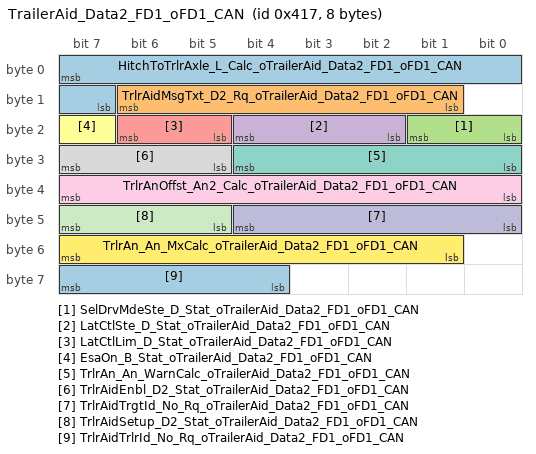
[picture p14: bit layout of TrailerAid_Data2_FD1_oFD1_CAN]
      frame TrailerAid_Data2_FD1_oFD1_CAN: id 0x417, from PSCM_FD, frame-length=8, variation-point=post-build-variant-condition{matching-criterion=Communication, value=0}, can-addressing-mode=STANDARD, can-frame-rx-behavior=ANY, can-frame-tx-behavior=CAN-FD
        pdu TrailerAid_Data2_FD1_oFD1_CAN: length=8, minimum-delay=0.02, transmission-mode-false-timing={cyclic-timing={time-offset=0, time-period=1}, event-controlled-timing={number-of-repetitions=0, repetition-period=0}}, transmission-mode-true-timing={cyclic-timing={time-offset=0, time-period=1}, event-controlled-timing={number-of-repetitions=0, repetition-period=0}}, unused-bit-pattern=0
          signal HitchToTrlrAxle_L_Calc_oTrailerAid_Data2_FD1_oFD1_CAN: start 7, 9 bit, big-endian, init-value=0, base-type=uint16, compu-method=CM_HitchToTrlrAxle_L_Calc, unit=U_meter, transfer-property=PENDING
          signal TrlrAidMsgTxt_D2_Rq_oTrailerAid_Data2_FD1_oFD1_CAN: start 14, 6 bit, big-endian, init-value=0, base-type=uint8, compu-method=CM_TrlrAidMsgTxt_D2_Rq, unit=U_SED, transfer-property=TRIGGERED-ON-CHANGE-WITHOUT-REPETITION
          signal SelDrvMdeSte_D_Stat_oTrailerAid_Data2_FD1_oFD1_CAN: start 17, 2 bit, big-endian, init-value=0, base-type=uint8, compu-method=CM_SelDrvMdeSte_D_Stat, unit=U_SED, transfer-property=TRIGGERED-ON-CHANGE-WITHOUT-REPETITION
          signal LatCtlSte_D_Stat_oTrailerAid_Data2_FD1_oFD1_CAN: start 20, 3 bit, big-endian, init-value=0, base-type=uint8, compu-method=CM_LatCtlSte_D_Stat, unit=U_SED, transfer-property=TRIGGERED-ON-CHANGE-WITHOUT-REPETITION
          signal LatCtlLim_D_Stat_oTrailerAid_Data2_FD1_oFD1_CAN: start 22, 2 bit, big-endian, init-value=0, base-type=uint8, compu-method=CM_LatCtlLim_D_Stat, unit=U_SED, transfer-property=TRIGGERED-ON-CHANGE-WITHOUT-REPETITION
          signal EsaOn_B_Stat_oTrailerAid_Data2_FD1_oFD1_CAN: start 23, 1 bit, big-endian, init-value=1, base-type=boolean, compu-method=CM_EsaOn_B_Stat, unit=U_SED, transfer-property=TRIGGERED-ON-CHANGE-WITHOUT-REPETITION
          signal TrlrAn_An_WarnCalc_oTrailerAid_Data2_FD1_oFD1_CAN: start 28, 5 bit, big-endian, init-value=0, base-type=uint8, compu-method=CM_TrlrAn_An_WarnCalc, unit=U_degrees, transfer-property=PENDING
          signal TrlrAidEnbl_D2_Stat_oTrailerAid_Data2_FD1_oFD1_CAN: start 31, 3 bit, big-endian, init-value=0, base-type=uint8, compu-method=CM_TrlrAidEnbl_D2_Stat, unit=U_SED, transfer-property=TRIGGERED-ON-CHANGE-WITHOUT-REPETITION
          signal TrlrAnOffst_An2_Calc_oTrailerAid_Data2_FD1_oFD1_CAN: start 39, 8 bit, big-endian, init-value=128, base-type=uint8, compu-method=CM_TrlrAnOffst_An2_Calc, unit=U_degrees, transfer-property=PENDING
          signal TrlrAidTrgtId_No_Rq_oTrailerAid_Data2_FD1_oFD1_CAN: start 44, 5 bit, big-endian, init-value=0, base-type=uint8, compu-method=CM_TrlrAidTrgtId_No_Rq, unit=unitless, transfer-property=PENDING
          signal TrlrAidSetup_D2_Stat_oTrailerAid_Data2_FD1_oFD1_CAN: start 47, 3 bit, big-endian, init-value=0, base-type=uint8, compu-method=CM_TrlrAidSetup_D2_Stat, unit=U_SED, transfer-property=PENDING
          signal TrlrAn_An_MxCalc_oTrailerAid_Data2_FD1_oFD1_CAN: start 55, 7 bit, big-endian, init-value=0, base-type=uint8, compu-method=CM_TrlrAn_An_MxCalc, unit=U_degrees, transfer-property=PENDING
          signal TrlrAidTrlrId_No_Rq_oTrailerAid_Data2_FD1_oFD1_CAN: start 63, 4 bit, big-endian, init-value=0, base-type=uint8, compu-method=CM_TrlrAidTrlrId_No_Rq, unit=unitless, transfer-property=PENDING
      frame TrailerAid_Data3_FD1_oFD1_CAN: id 0x45C, to PSCM_FD, frame-length=8, can-addressing-mode=STANDARD, can-frame-rx-behavior=ANY, can-frame-tx-behavior=CAN-FD
        pdu TrailerAid_Data3_FD1_oFD1_CAN: length=8, minimum-delay=0.02, unused-bit-pattern=0
          signal TrlrAidSetup_D2_Rq_oTrailerAid_Data3_FD1_oFD1_CAN: start 4, 4 bit, big-endian, init-value=0, base-type=uint8, compu-method=CM_TrlrAidSetup_D2_Rq, unit=U_SED, transfer-property=PENDING, to PSCM_FD
          signal TrlrAidEnbl_D2_Rq_oTrailerAid_Data3_FD1_oFD1_CAN: start 7, 3 bit, big-endian, init-value=0, base-type=uint8, compu-method=CM_TrlrAidEnbl_D2_Rq, unit=U_SED, transfer-property=PENDING, to PSCM_FD
      frame TrailerAid_Stat1_FD1_oFD1_CAN: id 0x452, to PSCM_FD, frame-length=8, can-addressing-mode=STANDARD, can-frame-rx-behavior=ANY, can-frame-tx-behavior=CAN-FD  # new RCM Serial Trailer Aid (TrailerAid_Stat1) 48 bits
        pdu TrailerAid_Stat1_FD1_oFD1_CAN: length=8, minimum-delay=0.02, unused-bit-pattern=0
          signal TrlrSnsId_No_Actl_oTrailerAid_Stat1_FD1_oFD1_CAN: start 0, 48 bit, opaque, init-value=6 x 0, base-type=uint8_6_iso_8859_1, compu-method=CM_TrlrSnsId_No_Actl, unit=unitless, transfer-property=PENDING, to PSCM_FD
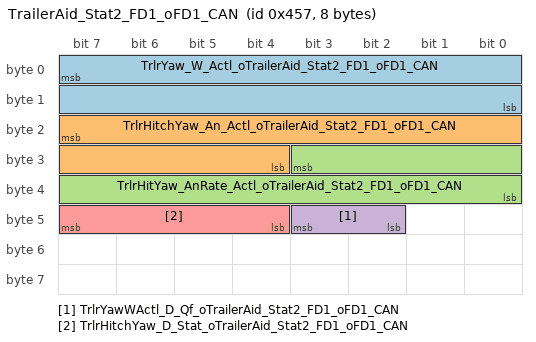
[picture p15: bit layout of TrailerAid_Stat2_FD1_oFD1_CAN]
      frame TrailerAid_Stat2_FD1_oFD1_CAN: id 0x457, to PSCM_FD, frame-length=8, can-addressing-mode=STANDARD, can-frame-rx-behavior=ANY, can-frame-tx-behavior=CAN-FD  # new RCM Serial Trailer Aid (TrailerAid_Stat1) 48 bits
        pdu TrailerAid_Stat2_FD1_oFD1_CAN: length=8, minimum-delay=0.02, unused-bit-pattern=0
          signal TrlrYaw_W_Actl_oTrailerAid_Stat2_FD1_oFD1_CAN: start 7, 16 bit, big-endian, init-value=65534, base-type=uint16, compu-method=CM_TrlrYaw_W_Actl, unit=U_radiansYsecond, transfer-property=PENDING, to PSCM_FD
          signal TrlrHitchYaw_An_Actl_oTrailerAid_Stat2_FD1_oFD1_CAN: start 23, 12 bit, big-endian, init-value=4094, base-type=uint16, compu-method=CM_TrlrHitchYaw_An_Actl, unit=U_degrees, transfer-property=PENDING, to PSCM_FD
          signal TrlrHitYaw_AnRate_Actl_oTrailerAid_Stat2_FD1_oFD1_CAN: start 27, 12 bit, big-endian, init-value=4094, base-type=uint16, compu-method=CM_TrlrHitYaw_AnRate_Actl, unit=U_degreesYsecond, transfer-property=PENDING, to PSCM_FD
          signal TrlrYawWActl_D_Qf_oTrailerAid_Stat2_FD1_oFD1_CAN: start 43, 2 bit, big-endian, init-value=1, base-type=uint8, compu-method=CM_TrlrYawWActl_D_Qf, unit=U_SED, transfer-property=PENDING, to PSCM_FD
          signal TrlrHitchYaw_D_Stat_oTrailerAid_Stat2_FD1_oFD1_CAN: start 47, 4 bit, big-endian, init-value=0, base-type=uint8, compu-method=CM_TrlrHitchYaw_D_Stat, unit=U_SED, transfer-property=PENDING, to PSCM_FD
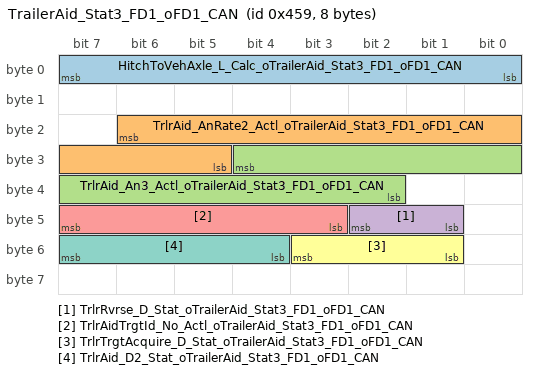
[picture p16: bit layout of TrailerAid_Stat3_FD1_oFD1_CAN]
      frame TrailerAid_Stat3_FD1_oFD1_CAN: id 0x459, to PSCM_FD, frame-length=8, can-addressing-mode=STANDARD, can-frame-rx-behavior=ANY, can-frame-tx-behavior=CAN-FD
        pdu TrailerAid_Stat3_FD1_oFD1_CAN: length=8, minimum-delay=0.02, transmission-mode-false-timing=cyclic-timing={time-offset=0, time-period=0.05}, transmission-mode-true-timing=cyclic-timing={time-offset=0, time-period=0.05}, unused-bit-pattern=0
          signal HitchToVehAxle_L_Calc_oTrailerAid_Stat3_FD1_oFD1_CAN: start 7, 8 bit, big-endian, init-value=255, base-type=uint8, compu-method=CM_HitchToVehAxle_L_Calc, unit=U_meter, transfer-property=PENDING, to PSCM_FD
          signal TrlrAid_AnRate2_Actl_oTrailerAid_Stat3_FD1_oFD1_CAN: start 22, 10 bit, big-endian, init-value=400, base-type=uint16, compu-method=CM_TrlrAid_AnRate2_Actl, unit=U_degreesYsecond, transfer-property=PENDING, to PSCM_FD
          signal TrlrAid_An3_Actl_oTrailerAid_Stat3_FD1_oFD1_CAN: start 28, 11 bit, big-endian, init-value=720, base-type=uint16, compu-method=CM_TrlrAid_An3_Actl, unit=U_degrees, transfer-property=PENDING, to PSCM_FD
          signal TrlrRvrse_D_Stat_oTrailerAid_Stat3_FD1_oFD1_CAN: start 42, 2 bit, big-endian, init-value=0, base-type=uint8, compu-method=CM_TrlrRvrse_D_Stat, unit=U_SED, transfer-property=PENDING, to PSCM_FD
          signal TrlrAidTrgtId_No_Actl_oTrailerAid_Stat3_FD1_oFD1_CAN: start 47, 5 bit, big-endian, init-value=0, base-type=uint8, compu-method=CM_TrlrAidTrgtId_No_Actl, unit=unitless, transfer-property=PENDING, to PSCM_FD
          signal TrlrTrgtAcquire_D_Stat_oTrailerAid_Stat3_FD1_oFD1_CAN: start 51, 3 bit, big-endian, init-value=0, base-type=uint8, compu-method=CM_TrlrTrgtAcquire_D_Stat, unit=U_SED, transfer-property=PENDING, to PSCM_FD
          signal TrlrAid_D2_Stat_oTrailerAid_Stat3_FD1_oFD1_CAN: start 55, 4 bit, big-endian, init-value=0, base-type=uint8, compu-method=CM_TrlrAid_D2_Stat, unit=U_SED, transfer-property=PENDING, to PSCM_FD
      frame TrailerBrakeInfo_FD1_oFD1_CAN: id 0x445, to PSCM_FD, frame-length=8, can-addressing-mode=STANDARD, can-frame-rx-behavior=ANY, can-frame-tx-behavior=CAN-FD
        pdu TrailerBrakeInfo_FD1_oFD1_CAN: length=8, minimum-delay=0.02, unused-bit-pattern=0
          signal TrlrBrkActCnnct_B_Actl_oTrailerBrakeInfo_FD1_oFD1_CAN: start 6, 1 bit, big-endian, init-value=0, base-type=boolean, compu-method=CM_TrlrBrkActCnnct_B_Actl, unit=U_SED, transfer-property=PENDING, to PSCM_FD
      frame TrailerInfo_2_FD1_oFD1_CAN: id 0x47A, to PSCM_FD, frame-length=8, can-addressing-mode=STANDARD, can-frame-rx-behavior=ANY, can-frame-tx-behavior=CAN-FD
        pdu TrailerInfo_2_FD1_oFD1_CAN: length=8, minimum-delay=0.02, unused-bit-pattern=0
          signal TrlrAidCtl_U_RqDrv_oTrailerInfo_2_FD1_oFD1_CAN: start 31, 12 bit, big-endian, init-value=4094, base-type=uint16, compu-method=CM_TrlrAidCtl_U_RqDrv, unit=U_volt, transfer-property=PENDING, to PSCM_FD
          signal TrlrAidSwtch_D_RqDrv_oTrailerInfo_2_FD1_oFD1_CAN: start 35, 2 bit, big-endian, init-value=0, base-type=uint8, compu-method=CM_TrlrAidSwtch_D_RqDrv, unit=U_SED, transfer-property=PENDING, to PSCM_FD
      frame TrailerInfo_FD1_oFD1_CAN: id 0x443, to PSCM_FD, frame-length=8, can-addressing-mode=STANDARD, can-frame-rx-behavior=ANY, can-frame-tx-behavior=CAN-FD
        pdu TrailerInfo_FD1_oFD1_CAN: length=8, minimum-delay=0.02, unused-bit-pattern=0
          signal TrlrLampCnnct_B_Actl_oTrailerInfo_FD1_oFD1_CAN: start 7, 1 bit, big-endian, init-value=0, base-type=boolean, compu-method=CM_TrlrLampCnnct_B_Actl, unit=U_SED, transfer-property=PENDING, to PSCM_FD
      frame TransGearData_FD1_oFD1_CAN: id 0x230, to PSCM_FD, frame-length=8, can-addressing-mode=STANDARD, can-frame-rx-behavior=ANY, can-frame-tx-behavior=CAN-FD  # MHT (U611/625) the HPCM will Rx 0x230 from the PCM_HEV Powersplit FWD HEVs (Cx482/3 430) the HPCM will Tx 0x230
        pdu TransGearData_FD1_oFD1_CAN: length=8, minimum-delay=0.01, transmission-mode-false-timing=cyclic-timing={time-offset=0, time-period=0.02}, transmission-mode-true-timing=cyclic-timing={time-offset=0, time-period=0.02}, unused-bit-pattern=0
          signal GearLvrPos_D_Actl_oTransGearData_FD1_oFD1_CAN: start 12, 4 bit, big-endian, init-value=14, base-type=uint8, compu-method=CM_GearLvrPos_D_Actl, unit=U_SED, transfer-property=PENDING, to PSCM_FD
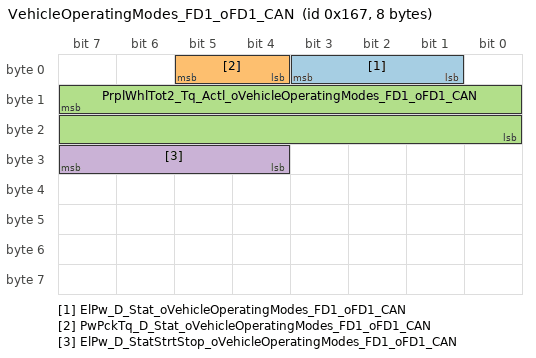
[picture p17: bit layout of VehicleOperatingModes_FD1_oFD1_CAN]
      frame VehicleOperatingModes_FD1_oFD1_CAN: id 0x167, to PSCM_FD, frame-length=8, can-addressing-mode=STANDARD, can-frame-rx-behavior=ANY, can-frame-tx-behavior=CAN-FD
        pdu VehicleOperatingModes_FD1_oFD1_CAN: length=8, minimum-delay=0, transmission-mode-false-timing=cyclic-timing={time-offset=0, time-period=0.01}, transmission-mode-true-timing=cyclic-timing={time-offset=0, time-period=0.01}, unused-bit-pattern=0
          signal ElPw_D_Stat_oVehicleOperatingModes_FD1_oFD1_CAN: start 3, 3 bit, big-endian, init-value=0, base-type=uint8, compu-method=CM_ElPw_D_Stat, unit=U_SED, transfer-property=PENDING, to PSCM_FD
          signal PwPckTq_D_Stat_oVehicleOperatingModes_FD1_oFD1_CAN: start 5, 2 bit, big-endian, init-value=0, base-type=uint8, compu-method=CM_PwPckTq_D_Stat, unit=U_SED, transfer-property=PENDING, to PSCM_FD
          signal PrplWhlTot2_Tq_Actl_oVehicleOperatingModes_FD1_oFD1_CAN: start 15, 16 bit, big-endian, init-value=0, base-type=uint16, compu-method=CM_PrplWhlTot2_Tq_Actl, unit=U_Nm, transfer-property=PENDING, to PSCM_FD
          signal ElPw_D_StatStrtStop_oVehicleOperatingModes_FD1_oFD1_CAN: start 31, 4 bit, big-endian, init-value=0, base-type=uint8, compu-method=CM_ElPw_D_StatStrtStop, unit=U_SED, transfer-property=PENDING, to PSCM_FD
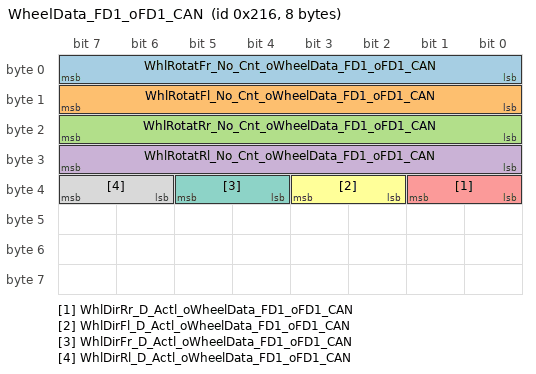
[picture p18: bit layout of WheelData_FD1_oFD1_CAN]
      frame WheelData_FD1_oFD1_CAN: id 0x216, to PSCM_FD, frame-length=8, can-addressing-mode=STANDARD, can-frame-rx-behavior=ANY, can-frame-tx-behavior=CAN-FD
        pdu WheelData_FD1_oFD1_CAN: length=8, minimum-delay=0.01, transmission-mode-false-timing=cyclic-timing={time-offset=0, time-period=0.02}, transmission-mode-true-timing=cyclic-timing={time-offset=0, time-period=0.02}, unused-bit-pattern=0
          signal WhlRotatFr_No_Cnt_oWheelData_FD1_oFD1_CAN: start 7, 8 bit, big-endian, init-value=0, base-type=uint8, compu-method=CM_WhlRotatFr_No_Cnt, unit=Unitless, transfer-property=PENDING, to PSCM_FD  # DCR 1833 to update Tx from GWM to EP100ms. Wheel Count signals are used by complex algorithm to determine Tire Pressure by Location & can't change from 20msec. (jweinfur)
          signal WhlRotatFl_No_Cnt_oWheelData_FD1_oFD1_CAN: start 15, 8 bit, big-endian, init-value=0, base-type=uint8, compu-method=CM_WhlRotatFl_No_Cnt, unit=Unitless, transfer-property=PENDING, to PSCM_FD  # DCR 1833 to update Tx from GWM to EP100ms. Wheel Count signals are used by complex algorithm to determine Tire Pressure by Location & can't change from 20msec. (jweinfur)
          signal WhlRotatRr_No_Cnt_oWheelData_FD1_oFD1_CAN: start 23, 8 bit, big-endian, init-value=0, base-type=uint8, compu-method=CM_WhlRotatRr_No_Cnt, unit=Unitless, transfer-property=PENDING, to PSCM_FD  # DCR 1833 to update Tx from GWM to EP100ms. Wheel Count signals are used by complex algorithm to determine Tire Pressure by Location & can't change from 20msec. (jweinfur)
          signal WhlRotatRl_No_Cnt_oWheelData_FD1_oFD1_CAN: start 31, 8 bit, big-endian, init-value=0, base-type=uint8, compu-method=CM_WhlRotatRl_No_Cnt, unit=Unitless, transfer-property=PENDING, to PSCM_FD  # DCR 1833 to update Tx from GWM to EP100ms. Wheel Count signals are used by complex algorithm to determine Tire Pressure by Location & can't change from 20msec. (jweinfur)
          signal WhlDirRr_D_Actl_oWheelData_FD1_oFD1_CAN: start 33, 2 bit, big-endian, init-value=0, base-type=uint8, compu-method=CM_WhlDirRr_D_Actl, unit=U_SED, transfer-property=PENDING, to PSCM_FD
          signal WhlDirFl_D_Actl_oWheelData_FD1_oFD1_CAN: start 35, 2 bit, big-endian, init-value=0, base-type=uint8, compu-method=CM_WhlDirFl_D_Actl, unit=U_SED, transfer-property=PENDING, to PSCM_FD
          signal WhlDirFr_D_Actl_oWheelData_FD1_oFD1_CAN: start 37, 2 bit, big-endian, init-value=0, base-type=uint8, compu-method=CM_WhlDirFr_D_Actl, unit=U_SED, transfer-property=PENDING, to PSCM_FD
          signal WhlDirRl_D_Actl_oWheelData_FD1_oFD1_CAN: start 39, 2 bit, big-endian, init-value=0, base-type=uint8, compu-method=CM_WhlDirRl_D_Actl, unit=U_SED, transfer-property=PENDING, to PSCM_FD
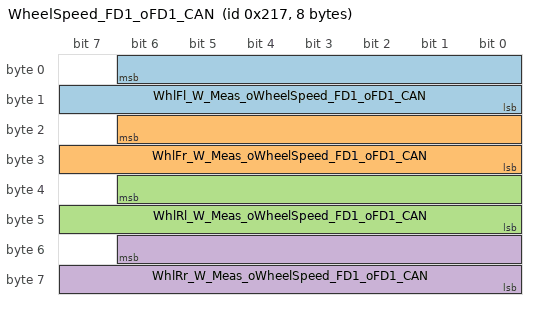
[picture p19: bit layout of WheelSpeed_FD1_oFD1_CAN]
      frame WheelSpeed_FD1_oFD1_CAN: id 0x217, to PSCM_FD, frame-length=8, can-addressing-mode=STANDARD, can-frame-rx-behavior=ANY, can-frame-tx-behavior=CAN-FD
        pdu WheelSpeed_FD1_oFD1_CAN: length=8, minimum-delay=0, transmission-mode-false-timing=cyclic-timing={time-offset=0, time-period=0.01}, transmission-mode-true-timing=cyclic-timing={time-offset=0, time-period=0.01}, unused-bit-pattern=0
          signal WhlFl_W_Meas_oWheelSpeed_FD1_oFD1_CAN: start 6, 15 bit, big-endian, init-value=0, base-type=uint16, compu-method=CM_WhlFl_W_Meas, unit=U_radYs, transfer-property=PENDING, to PSCM_FD
          signal WhlFr_W_Meas_oWheelSpeed_FD1_oFD1_CAN: start 22, 15 bit, big-endian, init-value=0, base-type=uint16, compu-method=CM_WhlFr_W_Meas, unit=U_radYs, transfer-property=PENDING, to PSCM_FD
          signal WhlRl_W_Meas_oWheelSpeed_FD1_oFD1_CAN: start 38, 15 bit, big-endian, init-value=0, base-type=uint16, compu-method=CM_WhlRl_W_Meas, unit=U_radYs, transfer-property=PENDING, to PSCM_FD
          signal WhlRr_W_Meas_oWheelSpeed_FD1_oFD1_CAN: start 54, 15 bit, big-endian, init-value=0, base-type=uint16, compu-method=CM_WhlRr_W_Meas, unit=U_radYs, transfer-property=PENDING, to PSCM_FD
      frame Xcp_CRO_Msg_oFD1_CAN: id 0x60A, to PSCM_FD, frame-length=8, variation-point=post-build-variant-condition{matching-criterion=Communication, value=0}, can-addressing-mode=STANDARD, can-frame-rx-behavior=ANY, can-frame-tx-behavior=CAN-20  # drecker 10/23/09 Need SAPP in sync w/Strg Torque for proper PAM interpretation, else fault msg's displayed FP@20ms IPC needs EPAS_Failure for msg to driver. Not map w/Lane Assist FP@30s FP), save bandwidth if feature not on vehicle
        xcp pdu Xcp_CRO_Msg_oFD1_CAN: length=8
      frame Xcp_DTO_Msg_oFD1_CAN: id 0x60B, from PSCM_FD, frame-length=8, variation-point=post-build-variant-condition{matching-criterion=Communication, value=0}, can-addressing-mode=STANDARD, can-frame-rx-behavior=ANY, can-frame-tx-behavior=CAN-20  # drecker 10/23/09 Need SAPP in sync w/Strg Torque for proper PAM interpretation, else fault msg's displayed FP@20ms IPC needs EPAS_Failure for msg to driver. Not map w/Lane Assist FP@30s FP), save bandwidth if feature not on vehicle
        xcp pdu Xcp_DTO_Msg_oFD1_CAN: length=8
      frame Yaw_Data_FD1_oFD1_CAN: id 0x91, to PSCM_FD, frame-length=8, can-addressing-mode=STANDARD, can-frame-rx-behavior=ANY, can-frame-tx-behavior=CAN-FD
        pdu Yaw_Data_FD1_oFD1_CAN: length=8, minimum-delay=0.02, unused-bit-pattern=0
          signal VehYaw_W_Actl_oYaw_Data_FD1_oFD1_CAN: start 23, 16 bit, big-endian, init-value=65534, base-type=uint16, compu-method=CM_VehYaw_W_Actl, unit=U_radYs, transfer-property=PENDING, to PSCM_FD  # CCMGenSigTimeoutTime=1000
      frame EPAS_INFO_FD1_oFD1_CAN: id 0x182, from PSCM_FD, frame-length=8, variation-point=post-build-variant-condition{matching-criterion=Communication, value=1}, can-addressing-mode=STANDARD, can-frame-rx-behavior=ANY, can-frame-tx-behavior=CAN-FD  # drecker 10/23/09 Need SAPP in sync w/Strg Torque for proper PAM interpretation, else fault msg's displayed FP@20ms IPC needs EPAS_Failure for msg to driver. Not map w/Lane Assist FP@30s FP), save bandwidth if feature not on vehicle
        carries pdu EPAS_INFO_FD1_oFD1_CAN: packing-byte-order=little-endian, start-position=0
      frame Lane_Assist_Data3_FD1_oFD1_CAN: id 0x4CC, from PSCM_FD, frame-length=8, variation-point=post-build-variant-condition{matching-criterion=Communication, value=1}, can-addressing-mode=STANDARD, can-frame-rx-behavior=ANY, can-frame-tx-behavior=CAN-FD
        carries pdu Lane_Assist_Data3_FD1_oFD1_CAN: packing-byte-order=little-endian, start-position=0
      frame PSCM_AutoSar_NetwrkMgt_FD1_oFD1_CAN: id 0x6B5, from PSCM_FD, frame-length=8, variation-point=post-build-variant-condition{matching-criterion=Communication, value=1}, can-addressing-mode=STANDARD, can-frame-rx-behavior=ANY, can-frame-tx-behavior=CAN-FD
        carries pdu PSCM_AutoSar_NetwrkMgt_FD1_oFD1_CAN: packing-byte-order=little-endian, start-position=0
      frame SteeringPinion_Data_FD1_oFD1_CAN: id 0x17E, from PSCM_FD, frame-length=8, variation-point=post-build-variant-condition{matching-criterion=Communication, value=1}, can-addressing-mode=STANDARD, can-frame-rx-behavior=ANY, can-frame-tx-behavior=CAN-FD
        carries pdu SteeringPinion_Data_FD1_oFD1_CAN: packing-byte-order=little-endian, start-position=0
      frame TesterFunctionalReq_FD1_oFD1_CAN: id 0x6DF, to PSCM_FD, frame-length=64, variation-point=post-build-variant-condition{matching-criterion=Communication, value=1}, can-addressing-mode=STANDARD, can-frame-rx-behavior=CAN-FD, can-frame-tx-behavior=CAN-FD  # OBDII Request ($7DF) messages are for FNOS 1.0.1 only. Diagnostic Functional Addressing ($7DF) and Dual Rate Periodic messages are for FNOS I3 only.
        carries pdu TesterFunctionalReq_FD1_Tp_oFD1_CAN: packing-byte-order=little-endian, start-position=0
      frame TesterFunctionalReq_FD1_oFD1_CAN_20: id 0x6DF, to PSCM_FD, frame-length=8, variation-point=post-build-variant-condition{matching-criterion=Communication, value=1}, can-addressing-mode=STANDARD, can-frame-rx-behavior=CAN-20, can-frame-tx-behavior=CAN-20
        carries pdu TesterFunctionalReq_FD1_Tp_oFD1_CAN_20: packing-byte-order=little-endian, start-position=0
      frame TesterPhysicalReqPSCM_FD1_oFD1_CAN: id 0x65E, to PSCM_FD, frame-length=64, variation-point=post-build-variant-condition{matching-criterion=Communication, value=1}, can-addressing-mode=STANDARD, can-frame-rx-behavior=CAN-FD, can-frame-tx-behavior=CAN-FD
        carries pdu TesterPhysicalReqPSCM_FD1_Tp_oFD1_CAN: packing-byte-order=little-endian, start-position=0
      frame TesterPhysicalReqPSCM_FD1_oFD1_CAN_20: id 0x65E, to PSCM_FD, frame-length=8, variation-point=post-build-variant-condition{matching-criterion=Communication, value=1}, can-addressing-mode=STANDARD, can-frame-rx-behavior=CAN-20, can-frame-tx-behavior=CAN-20
        carries pdu TesterPhysicalReqPSCM_FD1_Tp_oFD1_CAN_20: packing-byte-order=little-endian, start-position=0
      frame TesterPhysicalResPSCM_FD1_oFD1_CAN: id 0x65F, from PSCM_FD, frame-length=64, variation-point=post-build-variant-condition{matching-criterion=Communication, value=1}, can-addressing-mode=STANDARD, can-frame-rx-behavior=CAN-FD, can-frame-tx-behavior=CAN-FD
        carries pdu TesterPhysicalResPSCM_FD1_Tp_oFD1_CAN: packing-byte-order=little-endian, start-position=0
      frame TesterPhysicalResPSCM_FD1_oFD1_CAN_20: id 0x65F, from PSCM_FD, frame-length=8, variation-point=post-build-variant-condition{matching-criterion=Communication, value=1}, can-addressing-mode=STANDARD, can-frame-rx-behavior=CAN-20, can-frame-tx-behavior=CAN-20
        carries pdu TesterPhysicalResPSCM_FD1_Tp_oFD1_CAN_20: packing-byte-order=little-endian, start-position=0
      frame TrailerAid_Data2_FD1_oFD1_CAN: id 0x517, from PSCM_FD, frame-length=8, variation-point=post-build-variant-condition{matching-criterion=Communication, value=1}, can-addressing-mode=STANDARD, can-frame-rx-behavior=ANY, can-frame-tx-behavior=CAN-FD
        carries pdu TrailerAid_Data2_FD1_oFD1_CAN: packing-byte-order=little-endian, start-position=0
      frame Xcp_CRO_Msg_oFD1_CAN: id 0x660, to PSCM_FD, frame-length=8, variation-point=post-build-variant-condition{matching-criterion=Communication, value=1}, can-addressing-mode=STANDARD, can-frame-rx-behavior=ANY, can-frame-tx-behavior=CAN-20  # drecker 10/23/09 Need SAPP in sync w/Strg Torque for proper PAM interpretation, else fault msg's displayed FP@20ms IPC needs EPAS_Failure for msg to driver. Not map w/Lane Assist FP@30s FP), save bandwidth if feature not on vehicle
        carries pdu Xcp_CRO_Msg_oFD1_CAN: packing-byte-order=little-endian, start-position=0
      frame Xcp_DTO_Msg_oFD1_CAN: id 0x661, from PSCM_FD, frame-length=8, variation-point=post-build-variant-condition{matching-criterion=Communication, value=1}, can-addressing-mode=STANDARD, can-frame-rx-behavior=ANY, can-frame-tx-behavior=CAN-20  # drecker 10/23/09 Need SAPP in sync w/Strg Torque for proper PAM interpretation, else fault msg's displayed FP@20ms IPC needs EPAS_Failure for msg to driver. Not map w/Lane Assist FP@30s FP), save bandwidth if feature not on vehicle
        carries pdu Xcp_DTO_Msg_oFD1_CAN: packing-byte-order=little-endian, start-position=0
      pdu triggering PT_DeliveryVersion: pdu=DeliveryVersion_oFD1_CAN, to PSCM_FD
      pdu triggering PT_FileVersion: pdu=FileVersion_oFD1_CAN, to PSCM_FD
      pdu triggering PT_TesterFunctionalReq_FD1: pdu=TesterFunctionalReq_FD1_oFD1_CAN, to PSCM_FD
      pdu triggering PT_TesterFunctionalReq_FD1_20: pdu=TesterFunctionalReq_FD1_oFD1_CAN_20, to PSCM_FD
      pdu triggering PT_TesterPhysicalReqPSCM_FD1: pdu=TesterPhysicalReqPSCM_FD1_oFD1_CAN, to PSCM_FD
      pdu triggering PT_TesterPhysicalReqPSCM_FD1_20: pdu=TesterPhysicalReqPSCM_FD1_oFD1_CAN_20, to PSCM_FD
      pdu triggering PT_TesterPhysicalResPSCM_FD1: pdu=TesterPhysicalResPSCM_FD1_oFD1_CAN, from PSCM_FD
      pdu triggering PT_TesterPhysicalResPSCM_FD1_20: pdu=TesterPhysicalResPSCM_FD1_oFD1_CAN_20, from PSCM_FD
package /ECU
  ecu instance PSCM_FD: associated-com-i-pdu-group=[PSCM_FD_oFD1_CAN_Rx, PSCM_FD_oFD1_CAN_Tx]  # Passenger Front Climate Control Seat Module
    can communication controller CT_FD1_CAN
    can communication connector CN_FD1_CAN: comm-controller=CT_FD1_CAN
package /IPDUGroup
  i signal i pdu group PSCM_FD_oFD1_CAN_Rx: communication-direction=IN
    i-signal-i-pdus:
      ABS_BrkBst_Data_FD1_oFD1_CAN
      ActiveFrontStrg_Stat2_FD1_oFD1_CAN
      APIM_Send_Signals_2_FD1_oFD1_CAN
      APIM_Send_Signals1_FD1_oFD1_CAN
      Body_Info_4_FD1_oFD1_CAN
      BodyInfo_3_FD1_oFD1_CAN
      BrakeSnData_{3..6}_FD1_oFD1_CAN
      BrakeSysFeatures_3_oFD1_CAN
      BrakeSysFeatures_FD1_oFD1_CAN
      Climate_Control_Data_FD1_oFD1_CAN
      Cluster_Info1_FD1_oFD1_CAN
      DeliveryVersion_oFD1_CAN
      DesiredTorqBrk_FD1_oFD1_CAN
      EngBrakeData_FD1_oFD1_CAN
      EngVehicleSpThrottle_FD1_oFD1_CAN
      EngVehicleSpThrottle2_FD1_oFD1_CAN
      FileVersion_oFD1_CAN
      GGCC_Config_Mgmt_ID_1_FD1_oFD1_CAN
      Image_Processing_Data_FD1_oFD1_CAN
      Lane_Assist_Data1_FD1_oFD1_CAN
      LateralMotionControl_FD1_oFD1_CAN
      Mc_Send_Signals_2_FD1_oFD1_CAN
      ParkAid_Data_FD1_oFD1_CAN
      PowertrainData_10_FD1_oFD1_CAN
      Steer_Assist_Data_FD1_oFD1_CAN
      Steering_Data_FD1_oFD1_CAN
      TrailerAid_Data_FD1_oFD1_CAN
      TrailerAid_Data3_FD1_oFD1_CAN
      TrailerAid_Stat{1..3}_FD1_oFD1_CAN
      TrailerBrakeInfo_FD1_oFD1_CAN
      TrailerInfo_2_FD1_oFD1_CAN
      TrailerInfo_FD1_oFD1_CAN
      TransGearData_FD1_oFD1_CAN
      VehicleOperatingModes_FD1_oFD1_CAN
      WheelData_FD1_oFD1_CAN
      WheelSpeed_FD1_oFD1_CAN
      Yaw_Data_FD1_oFD1_CAN
  i signal i pdu group PSCM_FD_oFD1_CAN_Tx: communication-direction=OUT
    i-signal-i-pdus:
      EPAS_INFO_FD1_oFD1_CAN
      Lane_Assist_Data3_FD1_oFD1_CAN
      SteeringPinion_Data_FD1_oFD1_CAN
      TrailerAid_Data2_FD1_oFD1_CAN
package /PDU
  pdu DeliveryVersion_oFD1_CAN: length=10, unused-bit-pattern=0
    signal DeliverySipNumber_oDeliveryVersion_oFD1_CAN: start 0, 24 bit, little-endian, init-value=1507332, base-type=uint32, to PSCM_FD
    signal DeliverySubProjectNumber_oDeliveryVersion_oFD1_CAN: start 24, 32 bit, little-endian, init-value=23072854, base-type=uint32, to PSCM_FD
    signal DeliveryNumber_oDeliveryVersion_oFD1_CAN: start 56, 8 bit, little-endian, init-value=0, base-type=uint8, to PSCM_FD
    signal DeliveryIdle_oDeliveryVersion_oFD1_CAN: start 64, 16 bit, little-endian, init-value=0, base-type=uint16, to PSCM_FD
  pdu FileVersion_oFD1_CAN: length=4, unused-bit-pattern=0
    signal FileVersionYear_oFileVersion_oFD1_CAN: start 0, 8 bit, little-endian, init-value=23, base-type=uint8, to PSCM_FD
    signal FileVersionMonth_oFileVersion_oFD1_CAN: start 8, 8 bit, little-endian, init-value=17, base-type=uint8, to PSCM_FD
    signal FileVersionDay_oFileVersion_oFD1_CAN: start 16, 8 bit, little-endian, init-value=48, base-type=uint8, to PSCM_FD
    signal FileVersionNumber_oFileVersion_oFD1_CAN: start 24, 8 bit, little-endian, init-value=5, base-type=uint8, to PSCM_FD
  dcm i pdu TesterFunctionalReq_FD1_oFD1_CAN: length=62, diag-pdu-type=DIAG-REQUEST
  dcm i pdu TesterFunctionalReq_FD1_oFD1_CAN_20: length=7, diag-pdu-type=DIAG-REQUEST
  dcm i pdu TesterPhysicalReqPSCM_FD1_oFD1_CAN: length=64, diag-pdu-type=DIAG-REQUEST
  dcm i pdu TesterPhysicalReqPSCM_FD1_oFD1_CAN_20: length=8, diag-pdu-type=DIAG-REQUEST
  dcm i pdu TesterPhysicalResPSCM_FD1_oFD1_CAN: length=64, diag-pdu-type=DIAG-RESPONSE
  dcm i pdu TesterPhysicalResPSCM_FD1_oFD1_CAN_20: length=8, diag-pdu-type=DIAG-RESPONSE
